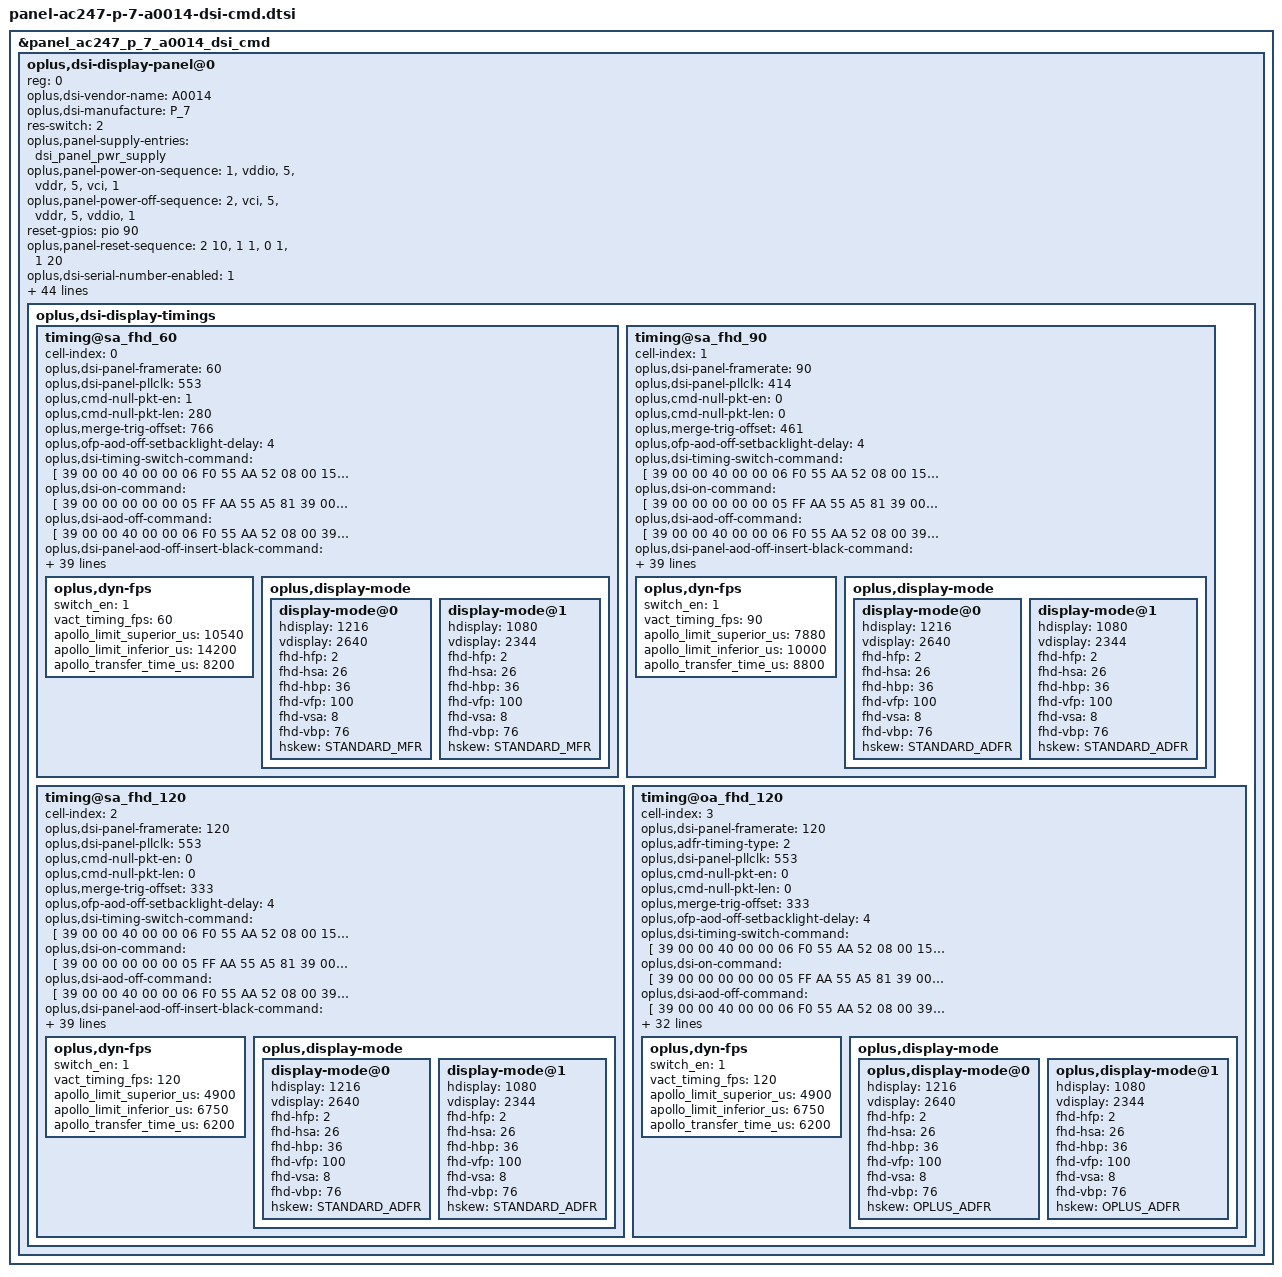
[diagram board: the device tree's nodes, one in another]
&panel_ac247_p_7_a0014_dsi_cmd {
	oplus,dsi-display-panel@0 {
		reg = <0>;
		oplus,dsi-vendor-name = "A0014";
		oplus,dsi-manufacture = "P_7";
		/* round corner */
		//#include "panel-ac247-p-7-a0014-dsi-cmd-round-corner.dtsi"
		oplus,dsi-display-timings {
			timing@sa_fhd_60 {
				cell-index = <0>;
				oplus,dsi-panel-framerate = <60>;
				oplus,dsi-panel-pllclk = <553>;
				oplus,cmd-null-pkt-en = <1>;
				oplus,cmd-null-pkt-len = <280>;
				oplus,merge-trig-offset = <766>;
				oplus,ofp-aod-off-setbacklight-delay = <4>;
				#include "panel-ac247-p-7-a0014-dsi-cmd-common.dtsi"
				oplus,dsi-timing-switch-command = [
					//2F:30->6D:01 60Hz(Repeat 1 times) --> 60Hz
					39 00 00 40 00 00 06 F0 55 AA 52 08 00
					15 00 00 40 00 00 02 6F 03
					39 00 00 40 00 00 03 35 00 01
					15 00 00 40 00 00 02 6F 20
					39 00 00 40 00 00 09 BA 00 01 03 03 00 01 03 03
					15 00 00 40 00 00 02 6F 30
					39 00 00 40 00 00 09 BA 00 01 03 0B 00 01 03 0B
					15 00 00 40 00 00 02 6F 40
					39 00 00 40 00 00 09 BA 00 01 03 17 00 01 03 17
					15 00 00 40 00 00 02 6F 50
					39 00 00 40 00 00 09 BA 00 01 03 77 00 01 03 77
					15 00 00 40 00 00 02 2F 30
					15 00 00 40 00 00 02 6D 01 //60Hz
					// DC/PWM fix
					39 00 00 40 00 00 06 F0 55 AA 52 08 09
					15 00 00 40 00 00 02 6F 1C
					39 00 00 40 00 00 06 BD 90 87 82 06 1C //Comp0_R_Gray0~4_DBV1
					15 00 00 40 00 00 02 6F 21
					39 00 00 40 00 00 06 BD 90 87 82 06 1C //Comp0_R_Gray0~4_DBV2
					15 00 00 40 00 00 02 6F 26
					39 00 00 40 00 00 06 BD 0A 07 02 86 97 //Comp0_R_Gray0~4_DBV3
					15 00 00 40 00 00 02 6F 2B
					39 00 00 40 00 00 06 BD 0A 07 02 86 97 //Comp0_R_Gray0~4_DBV4
					15 00 00 40 00 00 02 6F 3A
					39 00 00 40 00 00 06 BD 90 87 82 06 1C //Comp0_G_Gray0~4_DBV1
					15 00 00 40 00 00 02 6F 3F
					39 00 00 40 00 00 06 BD 90 87 82 06 1C //Comp0_G_Gray0~4_DBV1
					15 00 00 40 00 00 02 6F 44
					39 00 00 40 00 00 06 BD 0A 07 02 86 97 //Comp0_G_Gray0~4_DBV3
					15 00 00 40 00 00 02 6F 49
					39 00 00 40 00 00 06 BD 0A 07 02 86 97 //Comp0_G_Gray0~4_DBV4
					15 00 00 40 00 00 02 6F 58
					39 00 00 40 00 00 06 BD 90 87 82 06 1C //Comp0_B_Gray0~4_DBV1
					15 00 00 40 00 00 02 6F 5D
					39 00 00 40 00 00 06 BD 90 87 82 06 1C //Comp0_B_Gray0~4_DBV1
					15 00 00 40 00 00 02 6F 62
					39 00 00 40 00 00 06 BD 0A 07 02 86 97 //Co mp0_B_Gray0~4_DBV3
					15 00 00 40 00 00 02 6F 67
					39 00 00 00 00 00 06 BD 0A 07 02 86 97 //Comp0_B_Gray0~4_DBV4
				];
				oplus,dsi-on-command = [
					// init code
					39 00 00 00 00 00 05 FF AA 55 A5 81
					39 00 00 00 00 00 02 6F 0C
					39 00 00 00 00 00 02 FD 08
					39 00 00 00 00 00 02 6F 02
					39 00 00 00 00 00 02 F9 84
					39 00 00 00 00 00 02 6F 10
					39 00 00 00 00 00 02 FB 40
					39 00 00 00 00 00 05 FF AA 55 A5 80
					39 00 00 00 00 00 02 6F 48
					39 00 00 00 00 00 02 F2 00
					39 00 00 00 00 00 05 FF AA 55 A5 80
					39 00 00 00 00 00 02 6F 16
					39 00 00 00 00 00 03 F4 02 74
					39 00 00 00 00 00 05 FF AA 55 A5 80
					39 00 00 00 00 00 02 6F 42
					39 00 00 00 00 00 02 F4 00
					39 00 00 00 00 00 05 FF AA 55 A5 80
					39 00 00 00 00 00 02 6F 49
					39 00 00 00 00 00 02 F2 10
					39 00 00 00 00 00 05 FF AA 55 A5 81
					39 00 00 00 00 00 02 6F 05
					39 00 00 00 00 00 03 FE 3C 3C
					39 00 00 00 00 00 05 FF AA 55 A5 82
					39 00 00 00 00 00 02 6F 09
					39 00 00 00 00 00 02 F2 FF
					39 00 00 00 00 00 05 FF AA 55 A5 80
					39 00 00 00 00 00 02 6F 04
					39 00 00 00 00 00 02 F2 3C
					39 00 00 00 00 00 05 FF AA 55 A5 80
					39 00 00 00 00 00 02 6F 0A
					39 00 00 00 00 00 06 F6 70 70 70 70 70 //Power seq
					39 00 00 00 00 00 05 FF AA 55 A5 81
					39 00 00 00 00 00 02 6F 0D
					39 00 00 00 00 00 02 FB 80 // TE_opt
					39 00 00 00 00 00 06 F0 55 AA 52 08 01
					39 00 00 00 00 00 02 E5 00
					39 00 00 00 00 00 05 FF AA 55 A5 80
					39 00 00 00 00 00 02 6F 15
					39 00 00 00 00 00 03 F8 01 8C // DSPOSC=138.6MHz
					39 00 00 00 00 00 05 FF AA 55 A5 80
					39 00 00 00 00 00 02 6F 3E
					39 00 00 00 00 00 02 F8 00
					39 00 00 00 00 00 05 FF AA 55 A5 81
					39 00 00 00 00 00 02 6F 0B
					39 00 00 00 00 00 02 FD 04
					39 00 00 00 00 00 02 5A 01
					39 00 00 00 00 00 02 17 30
					39 00 00 00 00 00 03 5F 00 00
					39 00 00 00 00 00 02 35 00 // TE on
					39 00 00 00 00 00 0A 88 01 02 5F 09 4F 00 00 00 00
					39 00 00 00 00 00 02 53 20
					39 00 00 00 00 00 05 2A 00 00 04 BF
					39 00 00 00 00 00 05 2B 00 00 0A 4F
					39 00 00 00 00 00 02 90 03
					39 00 00 00 00 00 02 6F 01
					39 00 00 00 00 00 02 90 43
					39 00 00 00 00 00 13 91 AB A8 00 14 C2 00 02 31 02 05 00 08 05 0E 04 7B 10 E0 // VESA
					39 00 00 00 00 00 02 26 00
					39 00 00 00 00 00 02 6D 00
					39 00 00 00 00 00 02 6F 06
					39 00 00 00 00 00 02 6D 00
					// VFP/VBP SOP/GOP ON
					39 00 00 00 00 00 06 F0 55 AA 52 08 00
					15 00 00 00 00 00 02 6F 0D
					15 00 00 00 00 00 02 C2 0F
					//OSC：121.9-121.2 MHz
					39 00 00 00 00 00 05 FF AA 55 A5 80
					15 00 00 00 00 00 02 6F 31
					39 00 00 00 00 00 03 F8 01 B7
					// LFCC fix
					39 00 00 00 00 00 06 F0 55 AA 52 08 00
					15 00 00 00 00 00 02 6F 08
					15 00 00 00 00 00 02 B2 C0
					39 00 00 00 00 00 06 F0 55 AA 52 08 09
					//Comp_DBVPNTS0~5 = 423h,424h,48Ah,48Bh,4F0h,4F1h
					15 00 00 00 00 00 02 6F 01
					39 00 00 00 00 00 0A BD 44 23 24 44 8A 8B 44 F0 F1
					// Fixed TE
					15 00 00 00 00 00 02 5A 00
					15 00 00 00 00 00 02 6F 03
					15 00 00 00 00 00 02 5A 00
					39 00 00 00 00 00 03 44 00 00
					15 00 00 00 00 00 02 6F 04
					39 00 00 00 00 00 0D 44 00 00 00 00 00 00 00 00 00 00 00 00
					39 00 00 00 00 00 06 F0 55 AA 52 08 00
					15 00 00 00 00 00 02 BE 47
					// TEST TE
					39 00 00 00 00 00 06 F0 55 AA 52 08 00
					15 00 00 00 00 00 02 6F 01
					15 00 00 00 00 00 02 BE 54
					39 00 00 00 00 00 06 F0 55 AA 52 08 00
					15 00 00 00 00 00 02 6F 07
					39 00 00 00 00 00 06 B5 4E 2C 00 00 00 //Nor ELVSS 2.3V,ELVDD 4.8V
					15 00 00 00 00 00 02 6F 0C
					39 00 00 00 00 00 06 B5 4E 35 00 00 00 //AOD ELVSS 1.4V,ELVDD 4.8V
					//2F:30->6D:01 60Hz(Repeat 1 times) --> 60Hz
					39 00 00 00 00 00 06 F0 55 AA 52 08 00
					15 00 00 00 00 00 02 6F 03
					39 00 00 00 00 00 03 35 00 01
					15 00 00 00 00 00 02 6F 20
					39 00 00 00 00 00 09 BA 00 01 03 03 00 01 03 03
					15 00 00 00 00 00 02 6F 30
					39 00 00 00 00 00 09 BA 00 01 03 0B 00 01 03 0B
					15 00 00 00 00 00 02 6F 40
					39 00 00 00 00 00 09 BA 00 01 03 17 00 01 03 17
					15 00 00 00 00 00 02 6F 50
					39 00 00 00 00 00 09 BA 00 01 03 77 00 01 03 77
					15 00 00 00 00 00 02 2F 30
					15 00 00 00 00 00 02 6D 01 //60Hz
					// DC/PWM fix
					39 00 00 00 00 00 06 F0 55 AA 52 08 09
					15 00 00 00 00 00 02 6F 1C
					39 00 00 00 00 00 06 BD 90 87 82 06 1C //Comp0_R_Gray0~4_DBV1
					15 00 00 00 00 00 02 6F 21
					39 00 00 00 00 00 06 BD 90 87 82 06 1C //Comp0_R_Gray0~4_DBV2
					15 00 00 00 00 00 02 6F 26
					39 00 00 00 00 00 06 BD 0A 07 02 86 97 //Comp0_R_Gray0~4_DBV3
					15 00 00 00 00 00 02 6F 2B
					39 00 00 00 00 00 06 BD 0A 07 02 86 97 //Comp0_R_Gray0~4_DBV4
					15 00 00 00 00 00 02 6F 3A
					39 00 00 00 00 00 06 BD 90 87 82 06 1C //Comp0_G_Gray0~4_DBV1
					15 00 00 00 00 00 02 6F 3F
					39 00 00 00 00 00 06 BD 90 87 82 06 1C //Comp0_G_Gray0~4_DBV1
					15 00 00 00 00 00 02 6F 44
					39 00 00 00 00 00 06 BD 0A 07 02 86 97 //Comp0_G_Gray0~4_DBV3
					15 00 00 00 00 00 02 6F 49
					39 00 00 00 00 00 06 BD 0A 07 02 86 97 //Comp0_G_Gray0~4_DBV4
					15 00 00 00 00 00 02 6F 58
					39 00 00 00 00 00 06 BD 90 87 82 06 1C //Comp0_B_Gray0~4_DBV1
					15 00 00 00 00 00 02 6F 5D
					39 00 00 00 00 00 06 BD 90 87 82 06 1C //Comp0_B_Gray0~4_DBV1
					15 00 00 00 00 00 02 6F 62
					39 00 00 00 00 00 06 BD 0A 07 02 86 97 //Co mp0_B_Gray0~4_DBV3
					15 00 00 00 00 00 02 6F 67
					39 00 00 00 00 00 06 BD 0A 07 02 86 97 //Comp0_B_Gray0~4_DBV4
					// fix odc green ghosting
					39 00 00 00 00 00 06 F0 55 AA 52 08 08
					39 00 00 00 00 00 05 E0 21 01 01 01
					39 00 00 00 00 00 02 6F 35
					39 00 00 00 00 00 02 E2 00
					39 00 00 00 00 00 02 6F 43
					39 00 00 00 00 00 02 E2 00
					39 00 00 00 00 00 02 6F 51
					39 00 00 00 00 00 02 E2 00
					39 00 00 00 00 00 02 6F 5F
					39 00 00 00 00 00 02 E2 00
					39 00 00 00 00 00 02 6F 6D
					39 00 00 00 00 00 02 E2 00
					39 00 00 00 00 00 02 6F 7B
					39 00 00 00 00 00 02 E2 00
					// Demura LLC impro
					39 00 00 00 00 00 06 F0 55 AA 52 08 04
					39 00 00 00 00 00 08 E1 87 07 07 03 03 03 03
					15 00 00 00 00 00 02 6F 07
					39 00 00 00 00 00 05 03 01 01 01 01
					15 00 00 00 00 00 02 6F 0C
					39 00 00 00 00 00 08 E1 00 00 00 00 00 00 00
					15 00 00 00 00 00 02 6F 13
					39 00 00 00 00 00 05 00 00 00 00 00
					15 00 00 00 00 00 02 6F 18
					39 00 00 00 00 00 08 E1 07 07 07 03 03 03 03
					15 00 00 00 00 00 02 6F 1F
					39 00 00 00 00 00 05 03 01 01 01 01
					15 00 00 00 00 00 02 6F 24
					39 00 00 00 00 00 08 E1 01 03 15 1E 2E 3E 48
					15 00 00 00 00 00 02 6F 2B
					39 00 00 00 00 00 05 49 75 B1 DB FF
					// 3d lut inpro L240
					39 00 00 00 00 00 06 F0 55 AA 52 08 00
					39 00 00 00 00 00 02 6F 02
					39 00 00 00 00 00 07 E6 00 01 00 BC 01 5E
					39 00 00 00 00 00 02 6F 17
					39 00 00 00 00 00 02 E6 01
					39 00 00 00 00 00 06 F0 55 AA 52 08 00
					39 00 00 00 00 00 02 E6 80
					39 00 00 00 00 00 02 6F 00
					39 00 00 00 00 00 19 E7 00 00 00 00 00 00 00 00 00 00 00 00 00 00 00 00 00 00 00 00 00 00 00 00
					39 00 00 00 00 00 02 6F 18
					39 00 00 00 00 00 19 E7 00 40 40 40 40 40 40 40 40 40 40 40 40 40 40 40 40 40 40 40 40 40 40 40
					39 00 00 00 00 00 02 6F 30
					39 00 00 00 00 00 19 E7 40 40 80 80 80 80 80 80 80 80 80 80 80 80 80 80 80 80 80 80 80 80 80 80
					39 00 00 00 00 00 02 6F 48
					39 00 00 00 00 00 19 E7 80 80 80 C0 C0 C0 C0 C0 C0 C0 C0 C0 C0 C0 C0 C0 C0 C0 C0 C0 C0 C0 C0 C0
					39 00 00 00 00 00 02 6F 60
					39 00 00 00 00 00 19 E7 C0 C0 C0 C0 FF FF FF FF FF FF FF FF FF FF FF FF FF FF FF FF FF FF FF FF
					39 00 00 00 00 00 02 6F 78
					39 00 00 00 00 00 19 E7 FF FF FF FF FF 00 00 00 00 00 40 40 40 40 40 80 80 80 80 80 C0 C0 C0 C0
					39 00 00 00 00 00 02 6F 90
					39 00 00 00 00 00 19 E7 C0 FF FF FF FF FF 00 00 00 00 00 40 40 40 40 40 80 80 80 80 80 C0 C0 C0
					39 00 00 00 00 00 02 6F A8
					39 00 00 00 00 00 19 E7 C0 C0 FF FF FF FF FF 00 00 00 00 00 40 40 40 40 40 80 80 80 80 80 C0 C0
					39 00 00 00 00 00 02 6F C0
					39 00 00 00 00 00 19 E7 C0 C0 C0 FF FF FF FF FF 00 00 00 00 00 40 40 40 40 40 80 80 80 80 80 C0
					39 00 00 00 00 00 02 6F D8
					39 00 00 00 00 00 19 E7 C0 C0 C0 C0 FF FF FF FF FF 00 00 00 00 00 40 40 40 40 40 80 80 80 80 80
					39 00 00 00 00 00 02 6F 00
					39 00 00 00 00 00 19 E8 C0 C0 C0 C0 C0 FF FF FF FF FF 00 40 80 C0 FF 00 40 80 C0 FF 00 40 80 C0
					39 00 00 00 00 00 02 6F 18
					39 00 00 00 00 00 19 E8 FF 00 40 80 C0 FF 00 40 80 C0 FF 00 40 80 C0 FF 00 40 80 C0 FF 00 40 80
					39 00 00 00 00 00 02 6F 30
					39 00 00 00 00 00 19 E8 C0 FF 00 40 80 C0 FF 00 40 80 C0 FF 00 40 80 C0 FF 00 40 80 C0 FF 00 40
					39 00 00 00 00 00 02 6F 48
					39 00 00 00 00 00 19 E8 80 C0 FF 00 40 80 C0 FF 00 40 80 C0 FF 00 40 80 C0 FF 00 40 80 C0 FF 00
					39 00 00 00 00 00 02 6F 60
					39 00 00 00 00 00 19 E8 40 80 C0 FF 00 40 80 C0 FF 00 40 80 C0 FF 00 40 80 C0 FF 00 40 80 C0 FF
					39 00 00 00 00 00 02 6F 78
					39 00 00 00 00 00 19 E8 00 40 80 C0 FF 00 40 80 C0 FF 00 40 80 C0 FF 08 10 18 20 28 30 38 48 50
					39 00 00 00 00 00 02 6F 90
					39 00 00 00 00 00 19 E8 58 60 68 70 78 88 90 98 A0 A8 B0 B8 C8 D0 D8 E0 E8 F0 F8 08 10 18 20 28
					39 00 00 00 00 00 02 6F A8
					39 00 00 00 00 00 19 E8 30 38 48 50 58 60 68 70 78 88 90 98 A0 A8 B0 B8 C8 D0 D8 E0 E8 F0 F8 08
					39 00 00 00 00 00 02 6F C0
					39 00 00 00 00 00 19 E8 10 18 20 28 30 38 48 50 58 60 68 70 78 88 90 98 A0 A8 B0 B8 C8 D0 D8 E0
					39 00 00 00 00 00 02 6F D8
					39 00 00 00 00 00 19 E8 E8 F0 F8 10 10 00 20 10 10 10 00 10 10 20 10 00 10 10 10 10 20 00 00 00
					39 00 00 00 00 00 02 E6 00
					39 00 00 00 00 00 06 F0 55 AA 52 08 00
					39 00 00 00 00 00 02 E6 81
					39 00 00 00 00 00 02 6F 00
					39 00 00 00 00 00 19 E7 00 00 00 00 00 00 00 00 00 00 00 00 00 00 00 00 00 00 00 00 00 00 00 00
					39 00 00 00 00 00 02 6F 18
					39 00 00 00 00 00 19 E7 00 40 40 40 40 40 40 40 40 40 40 40 40 40 40 40 40 40 40 40 40 40 40 40
					39 00 00 00 00 00 02 6F 30
					39 00 00 00 00 00 19 E7 40 40 80 80 80 80 80 80 80 80 80 80 80 80 80 80 80 80 80 80 80 80 80 80
					39 00 00 00 00 00 02 6F 48
					39 00 00 00 00 00 19 E7 80 80 80 C0 C0 C0 C0 C0 C0 C0 C0 C0 C0 C0 C0 C0 C0 C0 C0 C0 C0 C0 C0 C0
					39 00 00 00 00 00 02 6F 60
					39 00 00 00 00 00 19 E7 C0 C0 C0 C0 FF FF FF FF FF FF FF FF FF FF FF FF FF FF FF FF FF FF FF FF
					39 00 00 00 00 00 02 6F 78
					39 00 00 00 00 00 19 E7 FF FF FF FF FF 00 00 00 00 00 40 40 40 40 40 80 80 80 80 80 C0 C0 C0 C0
					39 00 00 00 00 00 02 6F 90
					39 00 00 00 00 00 19 E7 C0 FF FF FF FF FF 00 00 00 00 00 40 40 40 40 40 80 80 80 80 80 C0 C0 C0
					39 00 00 00 00 00 02 6F A8
					39 00 00 00 00 00 19 E7 C0 C0 FF FF FF FF FF 00 00 00 00 00 40 40 40 40 40 80 80 80 80 80 C0 C0
					39 00 00 00 00 00 02 6F C0
					39 00 00 00 00 00 19 E7 C0 C0 C0 FF FF FF FF FF 00 00 00 00 00 40 40 40 40 40 80 80 80 80 80 C0
					39 00 00 00 00 00 02 6F D8
					39 00 00 00 00 00 19 E7 C0 C0 C0 C0 FF FF FF FF FF 00 00 00 00 00 40 40 40 40 40 80 80 80 80 80
					39 00 00 00 00 00 02 6F 00
					39 00 00 00 00 00 19 E8 C0 C0 C0 C0 C0 FF FF FF FF FF 00 40 80 C0 FF 00 40 80 C0 FF 00 40 80 C0
					39 00 00 00 00 00 02 6F 18
					39 00 00 00 00 00 19 E8 FF 00 40 80 C0 FF 00 40 80 C0 FF 00 40 80 C0 FF 00 40 80 C0 FF 00 40 80
					39 00 00 00 00 00 02 6F 30
					39 00 00 00 00 00 19 E8 C0 FF 00 40 80 C0 FF 00 40 80 C0 FF 00 40 80 C0 FF 00 40 80 C0 FF 00 40
					39 00 00 00 00 00 02 6F 48
					39 00 00 00 00 00 19 E8 80 C0 FF 00 40 80 C0 FF 00 40 80 C0 FF 00 40 80 C0 FF 00 40 80 C0 FF 00
					39 00 00 00 00 00 02 6F 60
					39 00 00 00 00 00 19 E8 40 80 C0 FF 00 40 80 C0 FF 00 40 80 C0 FF 00 40 80 C0 FF 00 40 80 C0 FF
					39 00 00 00 00 00 02 6F 78
					39 00 00 00 00 00 19 E8 00 40 80 C0 FF 00 40 80 C0 FF 00 40 80 C0 FF 08 10 18 20 28 30 38 48 50
					39 00 00 00 00 00 02 6F 90
					39 00 00 00 00 00 19 E8 58 60 68 70 78 86 8E 95 9D A5 AE B7 C8 D0 D8 E0 E8 F0 F8 08 10 18 20 28
					39 00 00 00 00 00 02 6F A8
					39 00 00 00 00 00 19 E8 30 38 48 50 58 60 68 70 78 88 90 98 A0 A8 B0 B8 C6 CD D4 DC E5 EE F8 08
					39 00 00 00 00 00 02 6F C0
					39 00 00 00 00 00 19 E8 10 18 20 28 30 38 48 50 58 60 68 70 78 88 90 98 A0 A8 B0 B8 C8 D0 D8 E0
					39 00 00 00 00 00 02 6F D8
					39 00 00 00 00 00 19 E8 E8 F0 F8 10 10 00 20 10 10 10 00 10 10 20 10 00 10 10 10 10 20 00 00 00
					39 00 00 00 00 00 02 E6 00
					39 00 00 00 00 00 06 F0 55 AA 52 08 00
					39 00 00 00 00 00 02 E6 82
					39 00 00 00 00 00 02 6F 00
					39 00 00 00 00 00 19 E7 00 00 00 00 00 00 00 00 00 00 00 00 00 00 00 00 00 00 00 00 00 00 00 00
					39 00 00 00 00 00 02 6F 18
					39 00 00 00 00 00 19 E7 00 40 40 40 40 40 40 40 40 40 40 40 40 40 40 40 40 40 40 40 40 40 40 40
					39 00 00 00 00 00 02 6F 30
					39 00 00 00 00 00 19 E7 40 40 80 80 80 80 80 80 80 80 80 80 80 80 80 80 80 80 80 80 80 80 80 80
					39 00 00 00 00 00 02 6F 48
					39 00 00 00 00 00 19 E7 80 80 80 C0 C0 C0 C0 C0 C0 C0 C0 C0 C0 C0 C0 C0 C0 C0 C0 C0 C0 C0 C0 C0
					39 00 00 00 00 00 02 6F 60
					39 00 00 00 00 00 19 E7 C0 C0 C0 C0 FF FF FF FF FF FF FF FF FF FF FF FF FF FF FF FF FF FF FF FF
					39 00 00 00 00 00 02 6F 78
					39 00 00 00 00 00 19 E7 FF FF FF FF FF 00 00 00 00 00 40 40 40 40 40 80 80 80 80 80 C0 C0 C0 C0
					39 00 00 00 00 00 02 6F 90
					39 00 00 00 00 00 19 E7 C0 FF FF FF FF FF 00 00 00 00 00 40 40 40 40 40 80 80 80 80 80 C0 C0 C0
					39 00 00 00 00 00 02 6F A8
					39 00 00 00 00 00 19 E7 C0 C0 FF FF FF FF FF 00 00 00 00 00 40 40 40 40 40 80 80 80 80 80 C0 C0
					39 00 00 00 00 00 02 6F C0
					39 00 00 00 00 00 19 E7 C0 C0 C0 FF FF FF FF FF 00 00 00 00 00 40 40 40 40 40 80 80 80 80 80 C0
					39 00 00 00 00 00 02 6F D8
					39 00 00 00 00 00 19 E7 C0 C0 C0 C0 FF FF FF FF FF 00 00 00 00 00 40 40 40 40 40 80 80 80 80 80
					39 00 00 00 00 00 02 6F 00
					39 00 00 00 00 00 19 E8 C0 C0 C0 C0 C0 FF FF FF FF FF 00 40 80 C0 FF 00 40 80 C0 FF 00 40 80 C0
					39 00 00 00 00 00 02 6F 18
					39 00 00 00 00 00 19 E8 FF 00 40 80 C0 FF 00 40 80 C0 FF 00 40 80 C0 FF 00 40 80 C0 FF 00 40 80
					39 00 00 00 00 00 02 6F 30
					39 00 00 00 00 00 19 E8 C0 FF 00 40 80 C0 FF 00 40 80 C0 FF 00 40 80 C0 FF 00 40 80 C0 FF 00 40
					39 00 00 00 00 00 02 6F 48
					39 00 00 00 00 00 19 E8 80 C0 FF 00 40 80 C0 FF 00 40 80 C0 FF 00 40 80 C0 FF 00 40 80 C0 FF 00
					39 00 00 00 00 00 02 6F 60
					39 00 00 00 00 00 19 E8 40 80 C0 FF 00 40 80 C0 FF 00 40 80 C0 FF 00 40 80 C0 FF 00 40 80 C0 FF
					39 00 00 00 00 00 02 6F 78
					39 00 00 00 00 00 19 E8 00 40 80 C0 FF 00 40 80 C0 FF 00 40 80 C0 FF 08 10 18 20 28 30 38 48 50
					39 00 00 00 00 00 02 6F 90
					39 00 00 00 00 00 19 E8 58 60 68 70 78 88 90 98 A0 A8 B0 B8 C8 D0 D8 E0 E8 F0 F8 08 10 18 20 28
					39 00 00 00 00 00 02 6F A8
					39 00 00 00 00 00 19 E8 30 38 48 50 58 60 68 70 78 88 90 98 A0 A8 B0 B8 C8 D0 D8 E0 E8 F0 F8 08
					39 00 00 00 00 00 02 6F C0
					39 00 00 00 00 00 19 E8 10 18 20 28 30 38 48 50 58 60 68 70 78 88 90 98 A0 A8 B0 B8 C8 D0 D8 E0
					39 00 00 00 00 00 02 6F D8
					39 00 00 00 00 00 19 E8 E8 F0 F8 10 10 00 20 10 10 10 00 10 10 20 10 00 10 10 10 10 20 00 00 00
					39 00 00 00 00 00 02 E6 00
					39 00 00 00 00 00 02 57 80
					//osc fixed
					39 00 00 00 00 00 06 F0 55 AA 52 08 01
					39 00 00 00 00 00 06 C3 DD 06 20 11 FF
					15 00 00 00 00 00 02 6F 05
					39 00 00 00 00 00 06 C3 00 06 20 11 FF
					15 00 00 00 00 00 02 6F 0A
					39 00 00 00 00 00 06 C3 00 07 0E 20 06
					15 00 00 00 00 00 02 6F 0F
					39 00 00 00 00 00 06 C3 44 19 07 11 18
					15 00 00 00 00 00 02 6F 14
					39 00 00 00 00 00 06 C3 06 5C 13 07 0E
					15 00 00 00 00 00 02 6F 19
					39 00 00 00 00 00 06 C3 20 06 44 19 07
					15 00 00 00 00 00 02 6F 1E
					39 00 00 00 00 00 06 C3 0E 20 06 44 19
					15 00 00 00 00 00 02 6F 23
					39 00 00 00 00 00 06 C3 07 0E 20 06 44
					15 00 00 00 00 00 02 6F 28
					15 00 00 00 00 00 02 C3 19
					//Modify power-off timing
					39 00 00 00 00 00 06 F0 55 AA 52 08 03
					15 00 00 00 00 00 02 6F 07
					15 00 00 00 00 00 02 C6 48
					//Light On
					39 00 00 00 78 00 01 11 // Sleep out
					39 00 00 00 00 00 01 29 // Display out
				];
				oplus,dsi-aod-off-command = [
					39 00 00 40 00 00 06 F0 55 AA 52 08 00
					39 00 00 40 00 00 02 2F 30
					39 00 00 40 00 00 02 6F 03
					39 00 00 40 00 00 03 35 00 01
					39 00 00 40 00 00 02 38 00
					05 00 00 40 00 00 01 2C
					39 00 00 40 00 00 03 51 00 00
					39 00 00 40 00 00 06 F0 55 AA 52 08 08
					39 00 00 40 00 00 02 BE 03
					39 00 00 40 00 00 05 FF AA 55 A5 81
					39 00 00 40 00 00 02 6F 0B
					39 00 00 00 00 00 02 FD 04 //gmaconv on
				];
				oplus,dsi-panel-aod-off-insert-black-command = [
					39 00 00 40 00 00 06 F0 55 AA 52 08 00
					39 00 00 40 00 00 02 2F 30
					39 00 00 40 00 00 02 6F 03
					39 00 00 40 00 00 03 35 00 01
					39 00 00 40 00 00 02 38 00
					39 00 00 40 00 00 03 51 00 00
					39 00 00 40 00 00 06 F0 55 AA 52 08 08
					39 00 00 40 00 00 02 BE 03
					39 00 00 40 00 00 05 FF AA 55 A5 81
					39 00 00 40 00 00 02 6F 0B
					39 00 00 00 00 00 02 FD 04 //gmaconv on
				];
				oplus,dsi-ultra-low-power-aod-on-command = [
					39 00 00 40 00 00 06 F0 55 AA 52 08 00
					39 00 00 40 00 00 02 6F 18
					39 00 00 00 00 00 06 BB 01 00 02 02 00
				];
				oplus,dsi-ultra-low-power-aod-off-command = [
					39 00 00 40 00 00 06 F0 55 AA 52 08 00
					39 00 00 40 00 00 02 6F 18
					39 00 00 00 00 00 06 BB 01 00 00 00 00
				];
				oplus,dsi-hbm-on-command = [
					39 00 00 00 00 00 03 51 0F FE
				];
				oplus,dsi-hbm-off-command = [
					39 00 00 00 00 00 03 51 0D BB
				];
				oplus,dsi-adfr-min-fps-60hz-command = [
					39 00 00 40 00 00 06 F0 55 AA 52 08 09
					15 00 00 40 00 00 02 6F 1C
					39 00 00 40 00 00 06 BD 90 87 82 06 1C
					15 00 00 40 00 00 02 6F 21
					39 00 00 40 00 00 06 BD 90 87 82 06 1C
					15 00 00 40 00 00 02 6F 26
					39 00 00 40 00 00 06 BD 0A 07 02 86 97
					15 00 00 40 00 00 02 6F 2B
					39 00 00 40 00 00 06 BD 0A 07 02 86 97
					15 00 00 40 00 00 02 6F 3A
					39 00 00 40 00 00 06 BD 90 87 82 06 1C
					15 00 00 40 00 00 02 6F 3F
					39 00 00 40 00 00 06 BD 90 87 82 06 1C
					15 00 00 40 00 00 02 6F 44
					39 00 00 40 00 00 06 BD 0A 07 02 86 97
					15 00 00 40 00 00 02 6F 49
					39 00 00 40 00 00 06 BD 0A 07 02 86 97
					15 00 00 40 00 00 02 6F 58
					39 00 00 40 00 00 06 BD 90 87 82 06 1C
					15 00 00 40 00 00 02 6F 5D
					39 00 00 40 00 00 06 BD 90 87 82 06 1C
					15 00 00 40 00 00 02 6F 62
					39 00 00 40 00 00 06 BD 0A 07 02 86 97
					15 00 00 40 00 00 02 6F 67
					39 00 00 40 00 00 06 BD 0A 07 02 86 97
					39 00 00 40 00 00 02 2F 30
					39 00 00 00 00 00 02 6D 01
				];
				oplus,dsi-adfr-min-fps-30hz-command = [
					39 00 00 40 00 00 06 F0 55 AA 52 08 09
					15 00 00 40 00 00 02 6F 1C
					39 00 00 40 00 00 06 BD 90 87 82 06 1C
					15 00 00 40 00 00 02 6F 21
					39 00 00 40 00 00 06 BD 90 87 82 06 1C
					15 00 00 40 00 00 02 6F 26
					39 00 00 40 00 00 06 BD 0A 07 02 86 97
					15 00 00 40 00 00 02 6F 2B
					39 00 00 40 00 00 06 BD 0A 07 02 86 97
					15 00 00 40 00 00 02 6F 3A
					39 00 00 40 00 00 06 BD 90 87 82 06 1C
					15 00 00 40 00 00 02 6F 3F
					39 00 00 40 00 00 06 BD 90 87 82 06 1C
					15 00 00 40 00 00 02 6F 44
					39 00 00 40 00 00 06 BD 0A 07 02 86 97
					15 00 00 40 00 00 02 6F 49
					39 00 00 40 00 00 06 BD 0A 07 02 86 97
					15 00 00 40 00 00 02 6F 58
					39 00 00 40 00 00 06 BD 90 87 82 06 1C
					15 00 00 40 00 00 02 6F 5D
					39 00 00 40 00 00 06 BD 90 87 82 06 1C
					15 00 00 40 00 00 02 6F 62
					39 00 00 40 00 00 06 BD 0A 07 02 86 97
					15 00 00 40 00 00 02 6F 67
					39 00 00 40 00 00 06 BD 0A 07 02 86 97
					39 00 00 40 00 00 02 2F 30
					39 00 00 00 00 00 02 6D 03
				];
				oplus,dsi-adfr-min-fps-10hz-command = [
					39 00 00 40 00 00 06 F0 55 AA 52 08 09
					15 00 00 40 00 00 02 6F 1C
					39 00 00 40 00 00 06 BD 90 87 82 06 1C
					15 00 00 40 00 00 02 6F 21
					39 00 00 40 00 00 06 BD 90 87 82 06 1C
					15 00 00 40 00 00 02 6F 26
					39 00 00 40 00 00 06 BD 0A 07 02 86 97
					15 00 00 40 00 00 02 6F 2B
					39 00 00 40 00 00 06 BD 0A 07 02 86 97
					15 00 00 40 00 00 02 6F 3A
					39 00 00 40 00 00 06 BD 90 87 82 06 1C
					15 00 00 40 00 00 02 6F 3F
					39 00 00 40 00 00 06 BD 90 87 82 06 1C
					15 00 00 40 00 00 02 6F 44
					39 00 00 40 00 00 06 BD 0A 07 02 86 97
					15 00 00 40 00 00 02 6F 49
					39 00 00 40 00 00 06 BD 0A 07 02 86 97
					15 00 00 40 00 00 02 6F 58
					39 00 00 40 00 00 06 BD 90 87 82 06 1C
					15 00 00 40 00 00 02 6F 5D
					39 00 00 40 00 00 06 BD 90 87 82 06 1C
					15 00 00 40 00 00 02 6F 62
					39 00 00 40 00 00 06 BD 0A 07 02 86 97
					15 00 00 40 00 00 02 6F 67
					39 00 00 40 00 00 06 BD 0A 07 02 86 97
					39 00 00 40 00 00 02 2F 30
					39 00 00 00 00 00 02 6D 05
				];
				oplus,dsi-adfr-min-fps-1hz-command = [
					39 00 00 40 00 00 06 F0 55 AA 52 08 09
					15 00 00 40 00 00 02 6F 1C
					39 00 00 40 00 00 06 BD 90 87 82 06 1C
					15 00 00 40 00 00 02 6F 21
					39 00 00 40 00 00 06 BD 90 87 82 06 1C
					15 00 00 40 00 00 02 6F 26
					39 00 00 40 00 00 06 BD 0A 07 02 86 97
					15 00 00 40 00 00 02 6F 2B
					39 00 00 40 00 00 06 BD 0A 07 02 86 97
					15 00 00 40 00 00 02 6F 3A
					39 00 00 40 00 00 06 BD 90 87 82 06 1C
					15 00 00 40 00 00 02 6F 3F
					39 00 00 40 00 00 06 BD 90 87 82 06 1C
					15 00 00 40 00 00 02 6F 44
					39 00 00 40 00 00 06 BD 0A 07 02 86 97
					15 00 00 40 00 00 02 6F 49
					39 00 00 40 00 00 06 BD 0A 07 02 86 97
					15 00 00 40 00 00 02 6F 58
					39 00 00 40 00 00 06 BD 90 87 82 06 1C
					15 00 00 40 00 00 02 6F 5D
					39 00 00 40 00 00 06 BD 90 87 82 06 1C
					15 00 00 40 00 00 02 6F 62
					39 00 00 40 00 00 06 BD 0A 07 02 86 97
					15 00 00 40 00 00 02 6F 67
					39 00 00 40 00 00 06 BD 0A 07 02 86 97
					39 00 00 40 00 00 02 2F 30
					39 00 00 00 00 00 02 6D 07
				];
				oplus,dsi-timing-switch-command-state = "dsi_hs_mode";
				oplus,dsi-on-command-state = "dsi_lp_mode";
				oplus,dsi-aod-off-command-state = "dsi_ls_mode";
				oplus,dsi-panel-aod-off-insert-black-command-state = "dsi_ls_mode";
				oplus,dsi-ultra-low-power-aod-on-command-state = "dsi_ls_mode";
				oplus,dsi-ultra-low-power-aod-off-command-state = "dsi_ls_mode";
				oplus,dsi-hbm-on-command-state = "dsi_hs_mode";
				oplus,dsi-hbm-off-command-state = "dsi_hs_mode";
				oplus,dsi-adfr-min-fps-60hz-command-state = "dsi_hs_mode";
				oplus,dsi-adfr-min-fps-30hz-command-state = "dsi_hs_mode";
				oplus,dsi-adfr-min-fps-10hz-command-state = "dsi_hs_mode";
				oplus,dsi-adfr-min-fps-1hz-command-state = "dsi_hs_mode";
				oplus,dsc-params-entries = <&dsc_params>;
				oplus,spr-params-entries = <&spr_params>;
				oplus,dyn-fps {
					switch_en = <1>;
					vact_timing_fps = <60>;
					apollo_limit_superior_us = <10540>;
					apollo_limit_inferior_us = <14200>;
					apollo_transfer_time_us = <8200>;
				};
				oplus,display-mode {
					display-mode@0 {
						hdisplay = <1216>;
						vdisplay = <2640>;
						fhd-hfp = <2>;
						fhd-hsa = <26>;
						fhd-hbp = <36>;
						fhd-vfp = <100>;
						fhd-vsa = <8>;
						fhd-vbp = <76>;
						hskew = <STANDARD_MFR>;
					};
					display-mode@1 {
						hdisplay = <1080>;
						vdisplay = <2344>;
						fhd-hfp = <2>;
						fhd-hsa = <26>;
						fhd-hbp = <36>;
						fhd-vfp = <100>;
						fhd-vsa = <8>;
						fhd-vbp = <76>;
						hskew = <STANDARD_MFR>;
					};
				};
			};
			timing@sa_fhd_90 {
				cell-index = <1>;
				oplus,dsi-panel-framerate = <90>;
				oplus,dsi-panel-pllclk = <414>;
				oplus,cmd-null-pkt-en = <0>;
				oplus,cmd-null-pkt-len = <0>;
				oplus,merge-trig-offset = <461>;
				oplus,ofp-aod-off-setbacklight-delay = <4>;
				#include "panel-ac247-p-7-a0014-dsi-cmd-common.dtsi"
				oplus,dsi-timing-switch-command = [
					//90HZ
					39 00 00 40 00 00 06 F0 55 AA 52 08 00
					15 00 00 40 00 00 02 6F 03
					39 00 00 40 00 00 03 35 00 00
					15 00 00 40 00 00 02 6F 20
					39 00 00 40 00 00 09 BA 00 01 02 02 00 01 02 02
					15 00 00 40 00 00 02 6F 30
					39 00 00 40 00 00 09 BA 00 01 02 08 00 01 02 08
					15 00 00 40 00 00 02 6F 40
					39 00 00 40 00 00 09 BA 00 01 02 11 00 01 02 11
					15 00 00 40 00 00 02 6F 50
					39 00 00 40 00 00 09 BA 00 01 02 59 00 01 02 59
					15 00 00 40 00 00 02 2F 31
					15 00 00 40 00 00 02 6D 08 //90Hz
					// DC/PWM fix
					39 00 00 40 00 00 06 F0 55 AA 52 08 09
					15 00 00 40 00 00 02 6F 1C
					39 00 00 40 00 00 06 BD 98 89 84 02 15 //Comp0_R_Gray0~4_DBV1
					15 00 00 40 00 00 02 6F 21
					39 00 00 40 00 00 06 BD 98 89 84 02 15 //Comp0_R_Gray0~4_DBV2
					15 00 00 40 00 00 02 6F 26
					39 00 00 40 00 00 06 BD 12 09 04 86 97 //Comp0_R_Gray0~4_DBV3
					15 00 00 40 00 00 02 6F 2B
					39 00 00 40 00 00 06 BD 12 09 04 86 97 //Comp0_R_Gray0~4_DBV4
					15 00 00 40 00 00 02 6F 3A
					39 00 00 40 00 00 06 BD 98 89 84 02 15 //Comp0_G_Gray0~4_DBV1
					15 00 00 40 00 00 02 6F 3F
					39 00 00 40 00 00 06 BD 98 89 84 02 15 //Comp0_G_Gray0~4_DBV1
					15 00 00 40 00 00 02 6F 44
					39 00 00 40 00 00 06 BD 12 09 04 86 97 //Comp0_G_Gray0~4_DBV3
					15 00 00 40 00 00 02 6F 49
					39 00 00 40 00 00 06 BD 12 09 04 86 97 //Comp0_G_Gray0~4_DBV4
					15 00 00 40 00 00 02 6F 58
					39 00 00 40 00 00 06 BD 98 89 84 02 15 //Comp 0_B_Gray0~4_DBV1
					15 00 00 40 00 00 02 6F 5D
					39 00 00 40 00 00 06 BD 98 89 84 02 15 //Comp0_B_Gray0~4_DBV1
					15 00 00 40 00 00 02 6F 62
					39 00 00 40 00 00 06 BD 12 09 04 86 97 //Comp0_B_Gray0~4_DBV3
					15 00 00 40 00 00 02 6F 67
					39 00 00 00 00 00 06 BD 12 09 04 86 97 //Comp0_B_Gray0~4_DBV4
				];
				oplus,dsi-on-command = [
					// init code
					39 00 00 00 00 00 05 FF AA 55 A5 81
					39 00 00 00 00 00 02 6F 0C
					39 00 00 00 00 00 02 FD 08
					39 00 00 00 00 00 02 6F 02
					39 00 00 00 00 00 02 F9 84
					39 00 00 00 00 00 02 6F 10
					39 00 00 00 00 00 02 FB 40
					39 00 00 00 00 00 05 FF AA 55 A5 80
					39 00 00 00 00 00 02 6F 48
					39 00 00 00 00 00 02 F2 00
					39 00 00 00 00 00 05 FF AA 55 A5 80
					39 00 00 00 00 00 02 6F 16
					39 00 00 00 00 00 03 F4 02 74
					39 00 00 00 00 00 05 FF AA 55 A5 80
					39 00 00 00 00 00 02 6F 42
					39 00 00 00 00 00 02 F4 00
					39 00 00 00 00 00 05 FF AA 55 A5 80
					39 00 00 00 00 00 02 6F 49
					39 00 00 00 00 00 02 F2 10
					39 00 00 00 00 00 05 FF AA 55 A5 81
					39 00 00 00 00 00 02 6F 05
					39 00 00 00 00 00 03 FE 3C 3C
					39 00 00 00 00 00 05 FF AA 55 A5 82
					39 00 00 00 00 00 02 6F 09
					39 00 00 00 00 00 02 F2 FF
					39 00 00 00 00 00 05 FF AA 55 A5 80
					39 00 00 00 00 00 02 6F 04
					39 00 00 00 00 00 02 F2 3C
					39 00 00 00 00 00 05 FF AA 55 A5 80
					39 00 00 00 00 00 02 6F 0A
					39 00 00 00 00 00 06 F6 70 70 70 70 70 //Power seq
					39 00 00 00 00 00 05 FF AA 55 A5 81
					39 00 00 00 00 00 02 6F 0D
					39 00 00 00 00 00 02 FB 80 // TE_opt
					39 00 00 00 00 00 06 F0 55 AA 52 08 01
					39 00 00 00 00 00 02 E5 00
					39 00 00 00 00 00 05 FF AA 55 A5 80
					39 00 00 00 00 00 02 6F 15
					39 00 00 00 00 00 03 F8 01 8C // DSPOSC=138.6MHz
					39 00 00 00 00 00 05 FF AA 55 A5 80
					39 00 00 00 00 00 02 6F 3E
					39 00 00 00 00 00 02 F8 00
					39 00 00 00 00 00 05 FF AA 55 A5 81
					39 00 00 00 00 00 02 6F 0B
					39 00 00 00 00 00 02 FD 04
					39 00 00 00 00 00 02 5A 01
					39 00 00 00 00 00 02 17 30
					39 00 00 00 00 00 03 5F 00 00
					39 00 00 00 00 00 02 35 00 // TE on
					39 00 00 00 00 00 0A 88 01 02 5F 09 4F 00 00 00 00
					39 00 00 00 00 00 02 53 20
					39 00 00 00 00 00 05 2A 00 00 04 BF
					39 00 00 00 00 00 05 2B 00 00 0A 4F
					39 00 00 00 00 00 02 90 03
					39 00 00 00 00 00 02 6F 01
					39 00 00 00 00 00 02 90 43
					39 00 00 00 00 00 13 91 AB A8 00 14 C2 00 02 31 02 05 00 08 05 0E 04 7B 10 E0 // VESA
					39 00 00 00 00 00 02 26 00
					39 00 00 00 00 00 02 6D 00
					39 00 00 00 00 00 02 6F 06
					39 00 00 00 00 00 02 6D 00
					// VFP/VBP SOP/GOP ON
					39 00 00 00 00 00 06 F0 55 AA 52 08 00
					15 00 00 00 00 00 02 6F 0D
					15 00 00 00 00 00 02 C2 0F
					//OSC：121.9-121.2 MHz
					39 00 00 00 00 00 05 FF AA 55 A5 80
					15 00 00 00 00 00 02 6F 31
					39 00 00 00 00 00 03 F8 01 B7
					// LFCC fix
					39 00 00 00 00 00 06 F0 55 AA 52 08 00
					15 00 00 00 00 00 02 6F 08
					15 00 00 00 00 00 02 B2 C0
					39 00 00 00 00 00 06 F0 55 AA 52 08 09
					//Comp_DBVPNTS0~5 = 423h,424h,48Ah,48Bh,4F0h,4F1h
					15 00 00 00 00 00 02 6F 01
					39 00 00 00 00 00 0A BD 44 23 24 44 8A 8B 44 F0 F1
					// Fixed TE
					15 00 00 00 00 00 02 5A 00
					15 00 00 00 00 00 02 6F 03
					15 00 00 00 00 00 02 5A 00
					39 00 00 00 00 00 03 44 00 00
					15 00 00 00 00 00 02 6F 04
					39 00 00 00 00 00 0D 44 00 00 00 00 00 00 00 00 00 00 00 00
					39 00 00 00 00 00 06 F0 55 AA 52 08 00
					15 00 00 00 00 00 02 BE 47
					// TEST TE
					39 00 00 00 00 00 06 F0 55 AA 52 08 00
					15 00 00 00 00 00 02 6F 01
					15 00 00 00 00 00 02 BE 54
					39 00 00 00 00 00 06 F0 55 AA 52 08 00
					15 00 00 00 00 00 02 6F 07
					39 00 00 00 00 00 06 B5 4E 2C 00 00 00 //Nor ELVSS 2.3V,ELVDD 4.8V
					15 00 00 00 00 00 02 6F 0C
					39 00 00 00 00 00 06 B5 4E 35 00 00 00 //AOD ELVSS 1.4V,ELVDD 4.8V
					//2F:30->6D:08 90Hz(Repeat 1 times) --> 90Hz
					39 00 00 00 00 00 06 F0 55 AA 52 08 00
					15 00 00 00 00 00 02 6F 03
					39 00 00 00 00 00 03 35 00 00
					15 00 00 00 00 00 02 6F 20
					39 00 00 00 00 00 09 BA 00 01 02 02 00 01 02 02
					15 00 00 00 00 00 02 6F 30
					39 00 00 00 00 00 09 BA 00 01 02 08 00 01 02 08
					15 00 00 00 00 00 02 6F 40
					39 00 00 00 00 00 09 BA 00 01 02 11 00 01 02 11
					15 00 00 00 00 00 02 6F 50
					39 00 00 00 00 00 09 BA 00 01 02 59 00 01 02 59
					15 00 00 00 00 00 02 2F 31
					15 00 00 00 00 00 02 6D 08 //90Hz
					// DC/PWM fix
					39 00 00 00 00 00 06 F0 55 AA 52 08 09
					15 00 00 00 00 00 02 6F 1C
					39 00 00 00 00 00 06 BD 98 89 84 02 15 //Comp0_R_Gray0~4_DBV1
					15 00 00 00 00 00 02 6F 21
					39 00 00 00 00 00 06 BD 98 89 84 02 15 //Comp0_R_Gray0~4_DBV2
					15 00 00 00 00 00 02 6F 26
					39 00 00 00 00 00 06 BD 12 09 04 86 97 //Comp0_R_Gray0~4_DBV3
					15 00 00 00 00 00 02 6F 2B
					39 00 00 00 00 00 06 BD 12 09 04 86 97 //Comp0_R_Gray0~4_DBV4
					15 00 00 00 00 00 02 6F 3A
					39 00 00 00 00 00 06 BD 98 89 84 02 15 //Comp0_G_Gray0~4_DBV1
					15 00 00 00 00 00 02 6F 3F
					39 00 00 00 00 00 06 BD 98 89 84 02 15 //Comp0_G_Gray0~4_DBV1
					15 00 00 00 00 00 02 6F 44
					39 00 00 00 00 00 06 BD 12 09 04 86 97 //Comp0_G_Gray0~4_DBV3
					15 00 00 00 00 00 02 6F 49
					39 00 00 00 00 00 06 BD 12 09 04 86 97 //Comp0_G_Gray0~4_DBV4
					15 00 00 00 00 00 02 6F 58
					39 00 00 00 00 00 06 BD 98 09 84 02 15 //Comp 0_B_Gray0~4_DBV1
					15 00 00 00 00 00 02 6F 5D
					39 00 00 00 00 00 06 BD 98 89 84 02 15 //Comp0_B_Gray0~4_DBV1
					15 00 00 00 00 00 02 6F 62
					39 00 00 00 00 00 06 BD 12 09 04 86 97 //Comp0_B_Gray0~4_DBV3
					15 00 00 00 00 00 02 6F 67
					39 00 00 00 00 00 06 BD 12 09 04 86 97 //Comp0_B_Gray0~4_DBV4
					// fix odc green ghosting
					39 00 00 00 00 00 06 F0 55 AA 52 08 08
					39 00 00 00 00 00 05 E0 21 01 01 01
					39 00 00 00 00 00 02 6F 35
					39 00 00 00 00 00 02 E2 00
					39 00 00 00 00 00 02 6F 43
					39 00 00 00 00 00 02 E2 00
					39 00 00 00 00 00 02 6F 51
					39 00 00 00 00 00 02 E2 00
					39 00 00 00 00 00 02 6F 5F
					39 00 00 00 00 00 02 E2 00
					39 00 00 00 00 00 02 6F 6D
					39 00 00 00 00 00 02 E2 00
					39 00 00 00 00 00 02 6F 7B
					39 00 00 00 00 00 02 E2 00
					// Demura LLC impro
					39 00 00 00 00 00 06 F0 55 AA 52 08 04
					39 00 00 00 00 00 08 E1 87 07 07 03 03 03 03
					15 00 00 00 00 00 02 6F 07
					39 00 00 00 00 00 05 03 01 01 01 01
					15 00 00 00 00 00 02 6F 0C
					39 00 00 00 00 00 08 E1 00 00 00 00 00 00 00
					15 00 00 00 00 00 02 6F 13
					39 00 00 00 00 00 05 00 00 00 00 00
					15 00 00 00 00 00 02 6F 18
					39 00 00 00 00 00 08 E1 07 07 07 03 03 03 03
					15 00 00 00 00 00 02 6F 1F
					39 00 00 00 00 00 05 03 01 01 01 01
					15 00 00 00 00 00 02 6F 24
					39 00 00 00 00 00 08 E1 01 03 15 1E 2E 3E 48
					15 00 00 00 00 00 02 6F 2B
					39 00 00 00 00 00 05 49 75 B1 DB FF
					// 3d lut inpro L240
					39 00 00 00 00 00 06 F0 55 AA 52 08 00
					39 00 00 00 00 00 02 6F 02
					39 00 00 00 00 00 07 E6 00 01 00 BC 01 5E
					39 00 00 00 00 00 02 6F 17
					39 00 00 00 00 00 02 E6 01
					39 00 00 00 00 00 06 F0 55 AA 52 08 00
					39 00 00 00 00 00 02 E6 80
					39 00 00 00 00 00 02 6F 00
					39 00 00 00 00 00 19 E7 00 00 00 00 00 00 00 00 00 00 00 00 00 00 00 00 00 00 00 00 00 00 00 00
					39 00 00 00 00 00 02 6F 18
					39 00 00 00 00 00 19 E7 00 40 40 40 40 40 40 40 40 40 40 40 40 40 40 40 40 40 40 40 40 40 40 40
					39 00 00 00 00 00 02 6F 30
					39 00 00 00 00 00 19 E7 40 40 80 80 80 80 80 80 80 80 80 80 80 80 80 80 80 80 80 80 80 80 80 80
					39 00 00 00 00 00 02 6F 48
					39 00 00 00 00 00 19 E7 80 80 80 C0 C0 C0 C0 C0 C0 C0 C0 C0 C0 C0 C0 C0 C0 C0 C0 C0 C0 C0 C0 C0
					39 00 00 00 00 00 02 6F 60
					39 00 00 00 00 00 19 E7 C0 C0 C0 C0 FF FF FF FF FF FF FF FF FF FF FF FF FF FF FF FF FF FF FF FF
					39 00 00 00 00 00 02 6F 78
					39 00 00 00 00 00 19 E7 FF FF FF FF FF 00 00 00 00 00 40 40 40 40 40 80 80 80 80 80 C0 C0 C0 C0
					39 00 00 00 00 00 02 6F 90
					39 00 00 00 00 00 19 E7 C0 FF FF FF FF FF 00 00 00 00 00 40 40 40 40 40 80 80 80 80 80 C0 C0 C0
					39 00 00 00 00 00 02 6F A8
					39 00 00 00 00 00 19 E7 C0 C0 FF FF FF FF FF 00 00 00 00 00 40 40 40 40 40 80 80 80 80 80 C0 C0
					39 00 00 00 00 00 02 6F C0
					39 00 00 00 00 00 19 E7 C0 C0 C0 FF FF FF FF FF 00 00 00 00 00 40 40 40 40 40 80 80 80 80 80 C0
					39 00 00 00 00 00 02 6F D8
					39 00 00 00 00 00 19 E7 C0 C0 C0 C0 FF FF FF FF FF 00 00 00 00 00 40 40 40 40 40 80 80 80 80 80
					39 00 00 00 00 00 02 6F 00
					39 00 00 00 00 00 19 E8 C0 C0 C0 C0 C0 FF FF FF FF FF 00 40 80 C0 FF 00 40 80 C0 FF 00 40 80 C0
					39 00 00 00 00 00 02 6F 18
					39 00 00 00 00 00 19 E8 FF 00 40 80 C0 FF 00 40 80 C0 FF 00 40 80 C0 FF 00 40 80 C0 FF 00 40 80
					39 00 00 00 00 00 02 6F 30
					39 00 00 00 00 00 19 E8 C0 FF 00 40 80 C0 FF 00 40 80 C0 FF 00 40 80 C0 FF 00 40 80 C0 FF 00 40
					39 00 00 00 00 00 02 6F 48
					39 00 00 00 00 00 19 E8 80 C0 FF 00 40 80 C0 FF 00 40 80 C0 FF 00 40 80 C0 FF 00 40 80 C0 FF 00
					39 00 00 00 00 00 02 6F 60
					39 00 00 00 00 00 19 E8 40 80 C0 FF 00 40 80 C0 FF 00 40 80 C0 FF 00 40 80 C0 FF 00 40 80 C0 FF
					39 00 00 00 00 00 02 6F 78
					39 00 00 00 00 00 19 E8 00 40 80 C0 FF 00 40 80 C0 FF 00 40 80 C0 FF 08 10 18 20 28 30 38 48 50
					39 00 00 00 00 00 02 6F 90
					39 00 00 00 00 00 19 E8 58 60 68 70 78 88 90 98 A0 A8 B0 B8 C8 D0 D8 E0 E8 F0 F8 08 10 18 20 28
					39 00 00 00 00 00 02 6F A8
					39 00 00 00 00 00 19 E8 30 38 48 50 58 60 68 70 78 88 90 98 A0 A8 B0 B8 C8 D0 D8 E0 E8 F0 F8 08
					39 00 00 00 00 00 02 6F C0
					39 00 00 00 00 00 19 E8 10 18 20 28 30 38 48 50 58 60 68 70 78 88 90 98 A0 A8 B0 B8 C8 D0 D8 E0
					39 00 00 00 00 00 02 6F D8
					39 00 00 00 00 00 19 E8 E8 F0 F8 10 10 00 20 10 10 10 00 10 10 20 10 00 10 10 10 10 20 00 00 00
					39 00 00 00 00 00 02 E6 00
					39 00 00 00 00 00 06 F0 55 AA 52 08 00
					39 00 00 00 00 00 02 E6 81
					39 00 00 00 00 00 02 6F 00
					39 00 00 00 00 00 19 E7 00 00 00 00 00 00 00 00 00 00 00 00 00 00 00 00 00 00 00 00 00 00 00 00
					39 00 00 00 00 00 02 6F 18
					39 00 00 00 00 00 19 E7 00 40 40 40 40 40 40 40 40 40 40 40 40 40 40 40 40 40 40 40 40 40 40 40
					39 00 00 00 00 00 02 6F 30
					39 00 00 00 00 00 19 E7 40 40 80 80 80 80 80 80 80 80 80 80 80 80 80 80 80 80 80 80 80 80 80 80
					39 00 00 00 00 00 02 6F 48
					39 00 00 00 00 00 19 E7 80 80 80 C0 C0 C0 C0 C0 C0 C0 C0 C0 C0 C0 C0 C0 C0 C0 C0 C0 C0 C0 C0 C0
					39 00 00 00 00 00 02 6F 60
					39 00 00 00 00 00 19 E7 C0 C0 C0 C0 FF FF FF FF FF FF FF FF FF FF FF FF FF FF FF FF FF FF FF FF
					39 00 00 00 00 00 02 6F 78
					39 00 00 00 00 00 19 E7 FF FF FF FF FF 00 00 00 00 00 40 40 40 40 40 80 80 80 80 80 C0 C0 C0 C0
					39 00 00 00 00 00 02 6F 90
					39 00 00 00 00 00 19 E7 C0 FF FF FF FF FF 00 00 00 00 00 40 40 40 40 40 80 80 80 80 80 C0 C0 C0
					39 00 00 00 00 00 02 6F A8
					39 00 00 00 00 00 19 E7 C0 C0 FF FF FF FF FF 00 00 00 00 00 40 40 40 40 40 80 80 80 80 80 C0 C0
					39 00 00 00 00 00 02 6F C0
					39 00 00 00 00 00 19 E7 C0 C0 C0 FF FF FF FF FF 00 00 00 00 00 40 40 40 40 40 80 80 80 80 80 C0
					39 00 00 00 00 00 02 6F D8
					39 00 00 00 00 00 19 E7 C0 C0 C0 C0 FF FF FF FF FF 00 00 00 00 00 40 40 40 40 40 80 80 80 80 80
					39 00 00 00 00 00 02 6F 00
					39 00 00 00 00 00 19 E8 C0 C0 C0 C0 C0 FF FF FF FF FF 00 40 80 C0 FF 00 40 80 C0 FF 00 40 80 C0
					39 00 00 00 00 00 02 6F 18
					39 00 00 00 00 00 19 E8 FF 00 40 80 C0 FF 00 40 80 C0 FF 00 40 80 C0 FF 00 40 80 C0 FF 00 40 80
					39 00 00 00 00 00 02 6F 30
					39 00 00 00 00 00 19 E8 C0 FF 00 40 80 C0 FF 00 40 80 C0 FF 00 40 80 C0 FF 00 40 80 C0 FF 00 40
					39 00 00 00 00 00 02 6F 48
					39 00 00 00 00 00 19 E8 80 C0 FF 00 40 80 C0 FF 00 40 80 C0 FF 00 40 80 C0 FF 00 40 80 C0 FF 00
					39 00 00 00 00 00 02 6F 60
					39 00 00 00 00 00 19 E8 40 80 C0 FF 00 40 80 C0 FF 00 40 80 C0 FF 00 40 80 C0 FF 00 40 80 C0 FF
					39 00 00 00 00 00 02 6F 78
					39 00 00 00 00 00 19 E8 00 40 80 C0 FF 00 40 80 C0 FF 00 40 80 C0 FF 08 10 18 20 28 30 38 48 50
					39 00 00 00 00 00 02 6F 90
					39 00 00 00 00 00 19 E8 58 60 68 70 78 86 8E 95 9D A5 AE B7 C8 D0 D8 E0 E8 F0 F8 08 10 18 20 28
					39 00 00 00 00 00 02 6F A8
					39 00 00 00 00 00 19 E8 30 38 48 50 58 60 68 70 78 88 90 98 A0 A8 B0 B8 C6 CD D4 DC E5 EE F8 08
					39 00 00 00 00 00 02 6F C0
					39 00 00 00 00 00 19 E8 10 18 20 28 30 38 48 50 58 60 68 70 78 88 90 98 A0 A8 B0 B8 C8 D0 D8 E0
					39 00 00 00 00 00 02 6F D8
					39 00 00 00 00 00 19 E8 E8 F0 F8 10 10 00 20 10 10 10 00 10 10 20 10 00 10 10 10 10 20 00 00 00
					39 00 00 00 00 00 02 E6 00
					39 00 00 00 00 00 06 F0 55 AA 52 08 00
					39 00 00 00 00 00 02 E6 82
					39 00 00 00 00 00 02 6F 00
					39 00 00 00 00 00 19 E7 00 00 00 00 00 00 00 00 00 00 00 00 00 00 00 00 00 00 00 00 00 00 00 00
					39 00 00 00 00 00 02 6F 18
					39 00 00 00 00 00 19 E7 00 40 40 40 40 40 40 40 40 40 40 40 40 40 40 40 40 40 40 40 40 40 40 40
					39 00 00 00 00 00 02 6F 30
					39 00 00 00 00 00 19 E7 40 40 80 80 80 80 80 80 80 80 80 80 80 80 80 80 80 80 80 80 80 80 80 80
					39 00 00 00 00 00 02 6F 48
					39 00 00 00 00 00 19 E7 80 80 80 C0 C0 C0 C0 C0 C0 C0 C0 C0 C0 C0 C0 C0 C0 C0 C0 C0 C0 C0 C0 C0
					39 00 00 00 00 00 02 6F 60
					39 00 00 00 00 00 19 E7 C0 C0 C0 C0 FF FF FF FF FF FF FF FF FF FF FF FF FF FF FF FF FF FF FF FF
					39 00 00 00 00 00 02 6F 78
					39 00 00 00 00 00 19 E7 FF FF FF FF FF 00 00 00 00 00 40 40 40 40 40 80 80 80 80 80 C0 C0 C0 C0
					39 00 00 00 00 00 02 6F 90
					39 00 00 00 00 00 19 E7 C0 FF FF FF FF FF 00 00 00 00 00 40 40 40 40 40 80 80 80 80 80 C0 C0 C0
					39 00 00 00 00 00 02 6F A8
					39 00 00 00 00 00 19 E7 C0 C0 FF FF FF FF FF 00 00 00 00 00 40 40 40 40 40 80 80 80 80 80 C0 C0
					39 00 00 00 00 00 02 6F C0
					39 00 00 00 00 00 19 E7 C0 C0 C0 FF FF FF FF FF 00 00 00 00 00 40 40 40 40 40 80 80 80 80 80 C0
					39 00 00 00 00 00 02 6F D8
					39 00 00 00 00 00 19 E7 C0 C0 C0 C0 FF FF FF FF FF 00 00 00 00 00 40 40 40 40 40 80 80 80 80 80
					39 00 00 00 00 00 02 6F 00
					39 00 00 00 00 00 19 E8 C0 C0 C0 C0 C0 FF FF FF FF FF 00 40 80 C0 FF 00 40 80 C0 FF 00 40 80 C0
					39 00 00 00 00 00 02 6F 18
					39 00 00 00 00 00 19 E8 FF 00 40 80 C0 FF 00 40 80 C0 FF 00 40 80 C0 FF 00 40 80 C0 FF 00 40 80
					39 00 00 00 00 00 02 6F 30
					39 00 00 00 00 00 19 E8 C0 FF 00 40 80 C0 FF 00 40 80 C0 FF 00 40 80 C0 FF 00 40 80 C0 FF 00 40
					39 00 00 00 00 00 02 6F 48
					39 00 00 00 00 00 19 E8 80 C0 FF 00 40 80 C0 FF 00 40 80 C0 FF 00 40 80 C0 FF 00 40 80 C0 FF 00
					39 00 00 00 00 00 02 6F 60
					39 00 00 00 00 00 19 E8 40 80 C0 FF 00 40 80 C0 FF 00 40 80 C0 FF 00 40 80 C0 FF 00 40 80 C0 FF
					39 00 00 00 00 00 02 6F 78
					39 00 00 00 00 00 19 E8 00 40 80 C0 FF 00 40 80 C0 FF 00 40 80 C0 FF 08 10 18 20 28 30 38 48 50
					39 00 00 00 00 00 02 6F 90
					39 00 00 00 00 00 19 E8 58 60 68 70 78 88 90 98 A0 A8 B0 B8 C8 D0 D8 E0 E8 F0 F8 08 10 18 20 28
					39 00 00 00 00 00 02 6F A8
					39 00 00 00 00 00 19 E8 30 38 48 50 58 60 68 70 78 88 90 98 A0 A8 B0 B8 C8 D0 D8 E0 E8 F0 F8 08
					39 00 00 00 00 00 02 6F C0
					39 00 00 00 00 00 19 E8 10 18 20 28 30 38 48 50 58 60 68 70 78 88 90 98 A0 A8 B0 B8 C8 D0 D8 E0
					39 00 00 00 00 00 02 6F D8
					39 00 00 00 00 00 19 E8 E8 F0 F8 10 10 00 20 10 10 10 00 10 10 20 10 00 10 10 10 10 20 00 00 00
					39 00 00 00 00 00 02 E6 00
					39 00 00 00 00 00 02 57 80
					//osc fixed
					39 00 00 00 00 00 06 F0 55 AA 52 08 01
					39 00 00 00 00 00 06 C3 DD 06 20 11 FF
					15 00 00 00 00 00 02 6F 05
					39 00 00 00 00 00 06 C3 00 06 20 11 FF
					15 00 00 00 00 00 02 6F 0A
					39 00 00 00 00 00 06 C3 00 07 0E 20 06
					15 00 00 00 00 00 02 6F 0F
					39 00 00 00 00 00 06 C3 44 19 07 11 18
					15 00 00 00 00 00 02 6F 14
					39 00 00 00 00 00 06 C3 06 5C 13 07 0E
					15 00 00 00 00 00 02 6F 19
					39 00 00 00 00 00 06 C3 20 06 44 19 07
					15 00 00 00 00 00 02 6F 1E
					39 00 00 00 00 00 06 C3 0E 20 06 44 19
					15 00 00 00 00 00 02 6F 23
					39 00 00 00 00 00 06 C3 07 0E 20 06 44
					15 00 00 00 00 00 02 6F 28
					15 00 00 00 00 00 02 C3 19
					//Modify power-off timing
					39 00 00 00 00 00 06 F0 55 AA 52 08 03
					15 00 00 00 00 00 02 6F 07
					15 00 00 00 00 00 02 C6 48
					//Light On
					39 00 00 00 78 00 01 11 // Sleep out
					39 00 00 00 00 00 01 29 // Display out
				];
				oplus,dsi-aod-off-command = [
					39 00 00 40 00 00 06 F0 55 AA 52 08 00
					39 00 00 40 00 00 02 2F 31
					39 00 00 40 00 00 02 6F 03
					39 00 00 40 00 00 03 35 00 00
					39 00 00 40 00 00 02 38 00
					05 00 00 40 00 00 01 2C
					39 00 00 40 00 00 03 51 00 00
					39 00 00 40 00 00 06 F0 55 AA 52 08 08
					39 00 00 40 00 00 02 BE 03
					39 00 00 40 00 00 05 FF AA 55 A5 81
					39 00 00 40 00 00 02 6F 0B
					39 00 00 00 00 00 02 FD 04 //gmaconv on
				];
				oplus,dsi-panel-aod-off-insert-black-command = [
					39 00 00 40 00 00 06 F0 55 AA 52 08 00
					39 00 00 40 00 00 02 2F 31
					39 00 00 40 00 00 02 6F 03
					39 00 00 40 00 00 03 35 00 00
					39 00 00 40 00 00 02 38 00
					39 00 00 40 00 00 03 51 00 00
					39 00 00 40 00 00 06 F0 55 AA 52 08 08
					39 00 00 40 00 00 02 BE 03
					39 00 00 40 00 00 05 FF AA 55 A5 81
					39 00 00 40 00 00 02 6F 0B
					39 00 00 00 00 00 02 FD 04 //gmaconv on
				];
				oplus,dsi-ultra-low-power-aod-on-command = [
					39 00 00 40 00 00 06 F0 55 AA 52 08 00
					39 00 00 40 00 00 02 6F 18
					39 00 00 00 00 00 06 BB 01 00 02 02 00
				];
				oplus,dsi-ultra-low-power-aod-off-command = [
					39 00 00 40 00 00 06 F0 55 AA 52 08 00
					39 00 00 40 00 00 02 6F 18
					39 00 00 00 00 00 06 BB 01 00 00 00 00
				];
				oplus,dsi-hbm-on-command = [
					39 00 00 00 00 00 03 51 0F FE
				];
				oplus,dsi-hbm-off-command = [
					39 00 00 00 00 00 03 51 0D BB
				];
				oplus,dsi-adfr-min-fps-90hz-command = [
					39 00 00 40 00 00 06 F0 55 AA 52 08 09
					15 00 00 40 00 00 02 6F 1C
					39 00 00 40 00 00 06 BD 98 89 84 02 15
					15 00 00 40 00 00 02 6F 21
					39 00 00 40 00 00 06 BD 98 89 84 02 15
					15 00 00 40 00 00 02 6F 26
					39 00 00 40 00 00 06 BD 12 09 04 86 97
					15 00 00 40 00 00 02 6F 2B
					39 00 00 40 00 00 06 BD 12 09 04 86 97
					15 00 00 40 00 00 02 6F 3A
					39 00 00 40 00 00 06 BD 98 89 84 02 15
					15 00 00 40 00 00 02 6F 3F
					39 00 00 40 00 00 06 BD 98 89 84 02 15
					15 00 00 40 00 00 02 6F 44
					39 00 00 40 00 00 06 BD 12 09 04 86 97
					15 00 00 40 00 00 02 6F 49
					39 00 00 40 00 00 06 BD 12 09 04 86 97
					15 00 00 40 00 00 02 6F 58
					39 00 00 40 00 00 06 BD 98 89 84 02 15
					15 00 00 40 00 00 02 6F 5D
					39 00 00 40 00 00 06 BD 98 89 84 02 15
					15 00 00 40 00 00 02 6F 62
					39 00 00 40 00 00 06 BD 12 09 04 86 97
					15 00 00 40 00 00 02 6F 67
					39 00 00 40 00 00 06 BD 12 09 04 86 97
					39 00 00 40 00 00 02 2F 31
					39 00 00 00 00 00 02 6D 08
				];
				oplus,dsi-adfr-min-fps-30hz-command = [
					39 00 00 40 00 00 06 F0 55 AA 52 08 09
					15 00 00 40 00 00 02 6F 1C
					39 00 00 40 00 00 06 BD 98 89 84 02 15
					15 00 00 40 00 00 02 6F 21
					39 00 00 40 00 00 06 BD 98 89 84 02 15
					15 00 00 40 00 00 02 6F 26
					39 00 00 40 00 00 06 BD 12 09 04 86 97
					15 00 00 40 00 00 02 6F 2B
					39 00 00 40 00 00 06 BD 12 09 04 86 97
					15 00 00 40 00 00 02 6F 3A
					39 00 00 40 00 00 06 BD 98 89 84 02 15
					15 00 00 40 00 00 02 6F 3F
					39 00 00 40 00 00 06 BD 98 89 84 02 15
					15 00 00 40 00 00 02 6F 44
					39 00 00 40 00 00 06 BD 12 09 04 86 97
					15 00 00 40 00 00 02 6F 49
					39 00 00 40 00 00 06 BD 12 09 04 86 97
					15 00 00 40 00 00 02 6F 58
					39 00 00 40 00 00 06 BD 98 89 84 02 15
					15 00 00 40 00 00 02 6F 5D
					39 00 00 40 00 00 06 BD 98 89 84 02 15
					15 00 00 40 00 00 02 6F 62
					39 00 00 40 00 00 06 BD 12 09 04 86 97
					15 00 00 40 00 00 02 6F 67
					39 00 00 40 00 00 06 BD 12 09 04 86 97
					39 00 00 40 00 00 02 2F 31
					39 00 00 00 00 00 02 6D 0A
				];
				oplus,dsi-adfr-min-fps-10hz-command = [
					39 00 00 40 00 00 06 F0 55 AA 52 08 09
					15 00 00 40 00 00 02 6F 1C
					39 00 00 40 00 00 06 BD 98 89 84 02 15
					15 00 00 40 00 00 02 6F 21
					39 00 00 40 00 00 06 BD 98 89 84 02 15
					15 00 00 40 00 00 02 6F 26
					39 00 00 40 00 00 06 BD 12 09 04 86 97
					15 00 00 40 00 00 02 6F 2B
					39 00 00 40 00 00 06 BD 12 09 04 86 97
					15 00 00 40 00 00 02 6F 3A
					39 00 00 40 00 00 06 BD 98 89 84 02 15
					15 00 00 40 00 00 02 6F 3F
					39 00 00 40 00 00 06 BD 98 89 84 02 15
					15 00 00 40 00 00 02 6F 44
					39 00 00 40 00 00 06 BD 12 09 04 86 97
					15 00 00 40 00 00 02 6F 49
					39 00 00 40 00 00 06 BD 12 09 04 86 97
					15 00 00 40 00 00 02 6F 58
					39 00 00 40 00 00 06 BD 98 89 84 02 15
					15 00 00 40 00 00 02 6F 5D
					39 00 00 40 00 00 06 BD 98 89 84 02 15
					15 00 00 40 00 00 02 6F 62
					39 00 00 40 00 00 06 BD 12 09 04 86 97
					15 00 00 40 00 00 02 6F 67
					39 00 00 40 00 00 06 BD 12 09 04 86 97
					39 00 00 40 00 00 02 2F 31
					39 00 00 00 00 00 02 6D 0C
				];
				oplus,dsi-adfr-min-fps-1hz-command = [
					39 00 00 40 00 00 06 F0 55 AA 52 08 09
					15 00 00 40 00 00 02 6F 1C
					39 00 00 40 00 00 06 BD 98 89 84 02 15
					15 00 00 40 00 00 02 6F 21
					39 00 00 40 00 00 06 BD 98 89 84 02 15
					15 00 00 40 00 00 02 6F 26
					39 00 00 40 00 00 06 BD 12 09 04 86 97
					15 00 00 40 00 00 02 6F 2B
					39 00 00 40 00 00 06 BD 12 09 04 86 97
					15 00 00 40 00 00 02 6F 3A
					39 00 00 40 00 00 06 BD 98 89 84 02 15
					15 00 00 40 00 00 02 6F 3F
					39 00 00 40 00 00 06 BD 98 89 84 02 15
					15 00 00 40 00 00 02 6F 44
					39 00 00 40 00 00 06 BD 12 09 04 86 97
					15 00 00 40 00 00 02 6F 49
					39 00 00 40 00 00 06 BD 12 09 04 86 97
					15 00 00 40 00 00 02 6F 58
					39 00 00 40 00 00 06 BD 98 89 84 02 15
					15 00 00 40 00 00 02 6F 5D
					39 00 00 40 00 00 06 BD 98 89 84 02 15
					15 00 00 40 00 00 02 6F 62
					39 00 00 40 00 00 06 BD 12 09 04 86 97
					15 00 00 40 00 00 02 6F 67
					39 00 00 40 00 00 06 BD 12 09 04 86 97
					39 00 00 40 00 00 02 2F 31
					39 00 00 00 00 00 02 6D 0E
				];
				oplus,dsi-timing-switch-command-state = "dsi_hs_mode";
				oplus,dsi-on-command-state = "dsi_lp_mode";
				oplus,dsi-aod-off-command-state = "dsi_ls_mode";
				oplus,dsi-panel-aod-off-insert-black-command-state = "dsi_ls_mode";
				oplus,dsi-ultra-low-power-aod-on-command-state = "dsi_ls_mode";
				oplus,dsi-ultra-low-power-aod-off-command-state = "dsi_ls_mode";
				oplus,dsi-hbm-on-command-state = "dsi_hs_mode";
				oplus,dsi-hbm-off-command-state = "dsi_hs_mode";
				oplus,dsi-adfr-min-fps-90hz-command-state = "dsi_hs_mode";
				oplus,dsi-adfr-min-fps-30hz-command-state = "dsi_hs_mode";
				oplus,dsi-adfr-min-fps-10hz-command-state = "dsi_hs_mode";
				oplus,dsi-adfr-min-fps-1hz-command-state = "dsi_hs_mode";
				oplus,dsc-params-entries = <&dsc_params>;
				oplus,spr-params-entries = <&spr_params>;
				oplus,dyn-fps {
					switch_en = <1>;
					vact_timing_fps = <90>;
					apollo_limit_superior_us = <7880>;
					apollo_limit_inferior_us = <10000>;
					apollo_transfer_time_us = <8800>;
				};
				oplus,display-mode {
					display-mode@0 {
						hdisplay = <1216>;
						vdisplay = <2640>;
						fhd-hfp = <2>;
						fhd-hsa = <26>;
						fhd-hbp = <36>;
						fhd-vfp = <100>;
						fhd-vsa = <8>;
						fhd-vbp = <76>;
						hskew = <STANDARD_ADFR>;
					};
					display-mode@1 {
						hdisplay = <1080>;
						vdisplay = <2344>;
						fhd-hfp = <2>;
						fhd-hsa = <26>;
						fhd-hbp = <36>;
						fhd-vfp = <100>;
						fhd-vsa = <8>;
						fhd-vbp = <76>;
						hskew = <STANDARD_ADFR>;
					};
				};
			};
			timing@sa_fhd_120 {
				cell-index = <2>;
				oplus,dsi-panel-framerate = <120>;
				oplus,dsi-panel-pllclk = <553>;
				oplus,cmd-null-pkt-en = <0>;
				oplus,cmd-null-pkt-len = <0>;
				oplus,merge-trig-offset = <333>;
				oplus,ofp-aod-off-setbacklight-delay = <4>;
				#include "panel-ac247-p-7-a0014-dsi-cmd-common.dtsi"
				oplus,dsi-timing-switch-command = [
					//120HZ
					39 00 00 40 00 00 06 F0 55 AA 52 08 00
					15 00 00 40 00 00 02 6F 03
					39 00 00 40 00 00 03 35 00 00
					15 00 00 40 00 00 02 6F 20
					39 00 00 40 00 00 09 BA 00 01 03 03 00 01 03 03
					15 00 00 40 00 00 02 6F 30
					39 00 00 40 00 00 09 BA 00 01 03 0B 00 01 03 0B
					15 00 00 40 00 00 02 6F 40
					39 00 00 40 00 00 09 BA 00 01 03 17 00 01 03 17
					15 00 00 40 00 00 02 6F 50
					39 00 00 40 00 00 09 BA 00 01 03 77 00 01 03 77
					15 00 00 40 00 00 02 2F 30
					15 00 00 40 00 00 02 6D 00 //120Hz
					// DC/PWM fix
					39 00 00 40 00 00 06 F0 55 AA 52 08 09
					15 00 00 40 00 00 02 6F 1C
					39 00 00 40 00 00 06 BD A0 89 84 02 15 //Comp0_R_Gray0~4_DBV1
					15 00 00 40 00 00 02 6F 21
					39 00 00 40 00 00 06 BD A0 89 84 02 15 //Comp0_R_Gray0~4_DBV2
					15 00 00 40 00 00 02 6F 26
					39 00 00 40 00 00 06 BD 14 09 04 86 97 //Comp0_R_Gray0~4_DBV3
					15 00 00 40 00 00 02 6F 2B
					39 00 00 40 00 00 06 BD 14 09 04 86 97 //Comp0_R_Gray0~4_DBV4
					15 00 00 40 00 00 02 6F 3A
					39 00 00 40 00 00 06 BD A0 89 84 02 15 //Comp0_G_Gray0~4_DBV1
					15 00 00 40 00 00 02 6F 3F
					39 00 00 40 00 00 06 BD A0 89 84 02 15 //Comp0_G_Gray0~4_DBV1
					15 00 00 40 00 00 02 6F 44
					39 00 00 40 00 00 06 BD 14 09 04 86 97 //Comp0_G_Gray0~4_DBV3
					15 00 00 40 00 00 02 6F 49
					39 00 00 40 00 00 06 BD 14 09 04 86 97 //Comp0_G_Gray0~4_DBV4
					15 00 00 40 00 00 02 6F 58
					39 00 00 40 00 00 06 BD A0 89 84 02 15 //Comp0_B_Gray0~4_DBV1
					15 00 00 40 00 00 02 6F 5D
					39 00 00 40 00 00 06 BD A0 89 84 02 15 //Comp0_B_Gray0~4_DBV1
					15 00 00 40 00 00 02 6F 62
					39 00 00 40 00 00 06 BD 14 09 04 86 97 //Comp0_B_Gray0~4_DBV3
					15 00 00 40 00 00 02 6F 67
					39 00 00 00 00 00 06 BD 14 09 04 86 97 //Comp0_B_Gray0~4_DBV4
				];
				oplus,dsi-on-command = [
					// init code
					39 00 00 00 00 00 05 FF AA 55 A5 81
					39 00 00 00 00 00 02 6F 0C
					39 00 00 00 00 00 02 FD 08
					39 00 00 00 00 00 02 6F 02
					39 00 00 00 00 00 02 F9 84
					39 00 00 00 00 00 02 6F 10
					39 00 00 00 00 00 02 FB 40
					39 00 00 00 00 00 05 FF AA 55 A5 80
					39 00 00 00 00 00 02 6F 48
					39 00 00 00 00 00 02 F2 00
					39 00 00 00 00 00 05 FF AA 55 A5 80
					39 00 00 00 00 00 02 6F 16
					39 00 00 00 00 00 03 F4 02 74
					39 00 00 00 00 00 05 FF AA 55 A5 80
					39 00 00 00 00 00 02 6F 42
					39 00 00 00 00 00 02 F4 00
					39 00 00 00 00 00 05 FF AA 55 A5 80
					39 00 00 00 00 00 02 6F 49
					39 00 00 00 00 00 02 F2 10
					39 00 00 00 00 00 05 FF AA 55 A5 81
					39 00 00 00 00 00 02 6F 05
					39 00 00 00 00 00 03 FE 3C 3C
					39 00 00 00 00 00 05 FF AA 55 A5 82
					39 00 00 00 00 00 02 6F 09
					39 00 00 00 00 00 02 F2 FF
					39 00 00 00 00 00 05 FF AA 55 A5 80
					39 00 00 00 00 00 02 6F 04
					39 00 00 00 00 00 02 F2 3C
					39 00 00 00 00 00 05 FF AA 55 A5 80
					39 00 00 00 00 00 02 6F 0A
					39 00 00 00 00 00 06 F6 70 70 70 70 70 //Power seq
					39 00 00 00 00 00 05 FF AA 55 A5 81
					39 00 00 00 00 00 02 6F 0D
					39 00 00 00 00 00 02 FB 80 // TE_opt
					39 00 00 00 00 00 06 F0 55 AA 52 08 01
					39 00 00 00 00 00 02 E5 00
					39 00 00 00 00 00 05 FF AA 55 A5 80
					39 00 00 00 00 00 02 6F 15
					39 00 00 00 00 00 03 F8 01 8C // DSPOSC=138.6MHz
					39 00 00 00 00 00 05 FF AA 55 A5 80
					39 00 00 00 00 00 02 6F 3E
					39 00 00 00 00 00 02 F8 00
					39 00 00 00 00 00 05 FF AA 55 A5 81
					39 00 00 00 00 00 02 6F 0B
					39 00 00 00 00 00 02 FD 04
					39 00 00 00 00 00 02 5A 01
					39 00 00 00 00 00 02 17 30
					39 00 00 00 00 00 03 5F 00 00
					39 00 00 00 00 00 02 35 00 // TE on
					39 00 00 00 00 00 0A 88 01 02 5F 09 4F 00 00 00 00
					39 00 00 00 00 00 02 53 20
					39 00 00 00 00 00 05 2A 00 00 04 BF
					39 00 00 00 00 00 05 2B 00 00 0A 4F
					39 00 00 00 00 00 02 90 03
					39 00 00 00 00 00 02 6F 01
					39 00 00 00 00 00 02 90 43
					39 00 00 00 00 00 13 91 AB A8 00 14 C2 00 02 31 02 05 00 08 05 0E 04 7B 10 E0 // VESA
					39 00 00 00 00 00 02 26 00
					39 00 00 00 00 00 02 6D 00
					39 00 00 00 00 00 02 6F 06
					39 00 00 00 00 00 02 6D 00
					// VFP/VBP SOP/GOP ON
					39 00 00 00 00 00 06 F0 55 AA 52 08 00
					15 00 00 00 00 00 02 6F 0D
					15 00 00 00 00 00 02 C2 0F
					//OSC：121.9-121.2 MHz
					39 00 00 00 00 00 05 FF AA 55 A5 80
					15 00 00 00 00 00 02 6F 31
					39 00 00 00 00 00 03 F8 01 B7
					// LFCC fix
					39 00 00 00 00 00 06 F0 55 AA 52 08 00
					15 00 00 00 00 00 02 6F 08
					15 00 00 00 00 00 02 B2 C0
					39 00 00 00 00 00 06 F0 55 AA 52 08 09
					//Comp_DBVPNTS0~5 = 423h,424h,48Ah,48Bh,4F0h,4F1h
					15 00 00 00 00 00 02 6F 01
					39 00 00 00 00 00 0A BD 44 23 24 44 8A 8B 44 F0 F1
					// Fixed TE
					15 00 00 00 00 00 02 5A 00
					15 00 00 00 00 00 02 6F 03
					15 00 00 00 00 00 02 5A 00
					39 00 00 00 00 00 03 44 00 00
					15 00 00 00 00 00 02 6F 04
					39 00 00 00 00 00 0D 44 00 00 00 00 00 00 00 00 00 00 00 00
					39 00 00 00 00 00 06 F0 55 AA 52 08 00
					15 00 00 00 00 00 02 BE 47
					// TEST TE
					39 00 00 00 00 00 06 F0 55 AA 52 08 00
					15 00 00 00 00 00 02 6F 01
					15 00 00 00 00 00 02 BE 54
					39 00 00 00 00 00 06 F0 55 AA 52 08 00
					15 00 00 00 00 00 02 6F 07
					39 00 00 00 00 00 06 B5 4E 2C 00 00 00 //Nor ELVSS 2.3V,ELVDD 4.8V
					15 00 00 00 00 00 02 6F 0C
					39 00 00 00 00 00 06 B5 4E 35 00 00 00 //AOD ELVSS 1.4V,ELVDD 4.8V
					//2F:30->6D:00 120Hz(Repeat 1 times) --> 120Hz
					39 00 00 00 00 00 06 F0 55 AA 52 08 00
					15 00 00 00 00 00 02 6F 03
					39 00 00 00 00 00 03 35 00 00
					15 00 00 00 00 00 02 6F 20
					39 00 00 00 00 00 09 BA 00 01 03 03 00 01 03 03
					15 00 00 00 00 00 02 6F 30
					39 00 00 00 00 00 09 BA 00 01 03 0B 00 01 03 0B
					15 00 00 00 00 00 02 6F 40
					39 00 00 00 00 00 09 BA 00 01 03 17 00 01 03 17
					15 00 00 00 00 00 02 6F 50
					39 00 00 00 00 00 09 BA 00 01 03 77 00 01 03 77
					15 00 00 00 00 00 02 2F 30
					15 00 00 00 00 00 02 6D 00 //120Hz
					// DC/PWM fix
					39 00 00 00 00 00 06 F0 55 AA 52 08 09
					15 00 00 00 00 00 02 6F 1C
					39 00 00 00 00 00 06 BD A0 89 84 02 15 //Comp0_R_Gray0~4_DBV1
					15 00 00 00 00 00 02 6F 21
					39 00 00 00 00 00 06 BD A0 89 84 02 15 //Comp0_R_Gray0~4_DBV2
					15 00 00 00 00 00 02 6F 26
					39 00 00 00 00 00 06 BD 14 09 04 86 97 //Comp0_R_Gray0~4_DBV3
					15 00 00 00 00 00 02 6F 2B
					39 00 00 00 00 00 06 BD 14 09 04 86 97 //Comp0_R_Gray0~4_DBV4
					15 00 00 00 00 00 02 6F 3A
					39 00 00 00 00 00 06 BD A0 89 84 02 15 //Comp0_G_Gray0~4_DBV1
					15 00 00 00 00 00 02 6F 3F
					39 00 00 00 00 00 06 BD A0 89 84 02 15 //Comp0_G_Gray0~4_DBV1
					15 00 00 00 00 00 02 6F 44
					39 00 00 00 00 00 06 BD 14 09 04 86 97 //Comp0_G_Gray0~4_DBV3
					15 00 00 00 00 00 02 6F 49
					39 00 00 00 00 00 06 BD 14 09 04 86 97 //Comp0_G_Gray0~4_DBV4
					15 00 00 00 00 00 02 6F 58
					39 00 00 00 00 00 06 BD A0 89 84 02 15 //Comp0_B_Gray0~4_DBV1
					15 00 00 00 00 00 02 6F 5D
					39 00 00 00 00 00 06 BD A0 89 84 02 15 //Comp0_B_Gray0~4_DBV1
					15 00 00 00 00 00 02 6F 62
					39 00 00 00 00 00 06 BD 04 09 04 86 97 //Comp0_B_Gray0~4_DBV3
					15 00 00 00 00 00 02 6F 67
					39 00 00 00 00 00 06 BD 14 09 04 86 97 //Comp0_B_Gray0~4_DBV4
					// fix odc green ghosting
					39 00 00 00 00 00 06 F0 55 AA 52 08 08
					39 00 00 00 00 00 05 E0 21 01 01 01
					39 00 00 00 00 00 02 6F 35
					39 00 00 00 00 00 02 E2 00
					39 00 00 00 00 00 02 6F 43
					39 00 00 00 00 00 02 E2 00
					39 00 00 00 00 00 02 6F 51
					39 00 00 00 00 00 02 E2 00
					39 00 00 00 00 00 02 6F 5F
					39 00 00 00 00 00 02 E2 00
					39 00 00 00 00 00 02 6F 6D
					39 00 00 00 00 00 02 E2 00
					39 00 00 00 00 00 02 6F 7B
					39 00 00 00 00 00 02 E2 00
					// Demura LLC impro
					39 00 00 00 00 00 06 F0 55 AA 52 08 04
					39 00 00 00 00 00 08 E1 87 07 07 03 03 03 03
					15 00 00 00 00 00 02 6F 07
					39 00 00 00 00 00 05 03 01 01 01 01
					15 00 00 00 00 00 02 6F 0C
					39 00 00 00 00 00 08 E1 00 00 00 00 00 00 00
					15 00 00 00 00 00 02 6F 13
					39 00 00 00 00 00 05 00 00 00 00 00
					15 00 00 00 00 00 02 6F 18
					39 00 00 00 00 00 08 E1 07 07 07 03 03 03 03
					15 00 00 00 00 00 02 6F 1F
					39 00 00 00 00 00 05 03 01 01 01 01
					15 00 00 00 00 00 02 6F 24
					39 00 00 00 00 00 08 E1 01 03 15 1E 2E 3E 48
					15 00 00 00 00 00 02 6F 2B
					39 00 00 00 00 00 05 49 75 B1 DB FF
					// 3d lut inpro L240
					39 00 00 00 00 00 06 F0 55 AA 52 08 00
					39 00 00 00 00 00 02 6F 02
					39 00 00 00 00 00 07 E6 00 01 00 BC 01 5E
					39 00 00 00 00 00 02 6F 17
					39 00 00 00 00 00 02 E6 01
					39 00 00 00 00 00 06 F0 55 AA 52 08 00
					39 00 00 00 00 00 02 E6 80
					39 00 00 00 00 00 02 6F 00
					39 00 00 00 00 00 19 E7 00 00 00 00 00 00 00 00 00 00 00 00 00 00 00 00 00 00 00 00 00 00 00 00
					39 00 00 00 00 00 02 6F 18
					39 00 00 00 00 00 19 E7 00 40 40 40 40 40 40 40 40 40 40 40 40 40 40 40 40 40 40 40 40 40 40 40
					39 00 00 00 00 00 02 6F 30
					39 00 00 00 00 00 19 E7 40 40 80 80 80 80 80 80 80 80 80 80 80 80 80 80 80 80 80 80 80 80 80 80
					39 00 00 00 00 00 02 6F 48
					39 00 00 00 00 00 19 E7 80 80 80 C0 C0 C0 C0 C0 C0 C0 C0 C0 C0 C0 C0 C0 C0 C0 C0 C0 C0 C0 C0 C0
					39 00 00 00 00 00 02 6F 60
					39 00 00 00 00 00 19 E7 C0 C0 C0 C0 FF FF FF FF FF FF FF FF FF FF FF FF FF FF FF FF FF FF FF FF
					39 00 00 00 00 00 02 6F 78
					39 00 00 00 00 00 19 E7 FF FF FF FF FF 00 00 00 00 00 40 40 40 40 40 80 80 80 80 80 C0 C0 C0 C0
					39 00 00 00 00 00 02 6F 90
					39 00 00 00 00 00 19 E7 C0 FF FF FF FF FF 00 00 00 00 00 40 40 40 40 40 80 80 80 80 80 C0 C0 C0
					39 00 00 00 00 00 02 6F A8
					39 00 00 00 00 00 19 E7 C0 C0 FF FF FF FF FF 00 00 00 00 00 40 40 40 40 40 80 80 80 80 80 C0 C0
					39 00 00 00 00 00 02 6F C0
					39 00 00 00 00 00 19 E7 C0 C0 C0 FF FF FF FF FF 00 00 00 00 00 40 40 40 40 40 80 80 80 80 80 C0
					39 00 00 00 00 00 02 6F D8
					39 00 00 00 00 00 19 E7 C0 C0 C0 C0 FF FF FF FF FF 00 00 00 00 00 40 40 40 40 40 80 80 80 80 80
					39 00 00 00 00 00 02 6F 00
					39 00 00 00 00 00 19 E8 C0 C0 C0 C0 C0 FF FF FF FF FF 00 40 80 C0 FF 00 40 80 C0 FF 00 40 80 C0
					39 00 00 00 00 00 02 6F 18
					39 00 00 00 00 00 19 E8 FF 00 40 80 C0 FF 00 40 80 C0 FF 00 40 80 C0 FF 00 40 80 C0 FF 00 40 80
					39 00 00 00 00 00 02 6F 30
					39 00 00 00 00 00 19 E8 C0 FF 00 40 80 C0 FF 00 40 80 C0 FF 00 40 80 C0 FF 00 40 80 C0 FF 00 40
					39 00 00 00 00 00 02 6F 48
					39 00 00 00 00 00 19 E8 80 C0 FF 00 40 80 C0 FF 00 40 80 C0 FF 00 40 80 C0 FF 00 40 80 C0 FF 00
					39 00 00 00 00 00 02 6F 60
					39 00 00 00 00 00 19 E8 40 80 C0 FF 00 40 80 C0 FF 00 40 80 C0 FF 00 40 80 C0 FF 00 40 80 C0 FF
					39 00 00 00 00 00 02 6F 78
					39 00 00 00 00 00 19 E8 00 40 80 C0 FF 00 40 80 C0 FF 00 40 80 C0 FF 08 10 18 20 28 30 38 48 50
					39 00 00 00 00 00 02 6F 90
					39 00 00 00 00 00 19 E8 58 60 68 70 78 88 90 98 A0 A8 B0 B8 C8 D0 D8 E0 E8 F0 F8 08 10 18 20 28
					39 00 00 00 00 00 02 6F A8
					39 00 00 00 00 00 19 E8 30 38 48 50 58 60 68 70 78 88 90 98 A0 A8 B0 B8 C8 D0 D8 E0 E8 F0 F8 08
					39 00 00 00 00 00 02 6F C0
					39 00 00 00 00 00 19 E8 10 18 20 28 30 38 48 50 58 60 68 70 78 88 90 98 A0 A8 B0 B8 C8 D0 D8 E0
					39 00 00 00 00 00 02 6F D8
					39 00 00 00 00 00 19 E8 E8 F0 F8 10 10 00 20 10 10 10 00 10 10 20 10 00 10 10 10 10 20 00 00 00
					39 00 00 00 00 00 02 E6 00
					39 00 00 00 00 00 06 F0 55 AA 52 08 00
					39 00 00 00 00 00 02 E6 81
					39 00 00 00 00 00 02 6F 00
					39 00 00 00 00 00 19 E7 00 00 00 00 00 00 00 00 00 00 00 00 00 00 00 00 00 00 00 00 00 00 00 00
					39 00 00 00 00 00 02 6F 18
					39 00 00 00 00 00 19 E7 00 40 40 40 40 40 40 40 40 40 40 40 40 40 40 40 40 40 40 40 40 40 40 40
					39 00 00 00 00 00 02 6F 30
					39 00 00 00 00 00 19 E7 40 40 80 80 80 80 80 80 80 80 80 80 80 80 80 80 80 80 80 80 80 80 80 80
					39 00 00 00 00 00 02 6F 48
					39 00 00 00 00 00 19 E7 80 80 80 C0 C0 C0 C0 C0 C0 C0 C0 C0 C0 C0 C0 C0 C0 C0 C0 C0 C0 C0 C0 C0
					39 00 00 00 00 00 02 6F 60
					39 00 00 00 00 00 19 E7 C0 C0 C0 C0 FF FF FF FF FF FF FF FF FF FF FF FF FF FF FF FF FF FF FF FF
					39 00 00 00 00 00 02 6F 78
					39 00 00 00 00 00 19 E7 FF FF FF FF FF 00 00 00 00 00 40 40 40 40 40 80 80 80 80 80 C0 C0 C0 C0
					39 00 00 00 00 00 02 6F 90
					39 00 00 00 00 00 19 E7 C0 FF FF FF FF FF 00 00 00 00 00 40 40 40 40 40 80 80 80 80 80 C0 C0 C0
					39 00 00 00 00 00 02 6F A8
					39 00 00 00 00 00 19 E7 C0 C0 FF FF FF FF FF 00 00 00 00 00 40 40 40 40 40 80 80 80 80 80 C0 C0
					39 00 00 00 00 00 02 6F C0
					39 00 00 00 00 00 19 E7 C0 C0 C0 FF FF FF FF FF 00 00 00 00 00 40 40 40 40 40 80 80 80 80 80 C0
					39 00 00 00 00 00 02 6F D8
					39 00 00 00 00 00 19 E7 C0 C0 C0 C0 FF FF FF FF FF 00 00 00 00 00 40 40 40 40 40 80 80 80 80 80
					39 00 00 00 00 00 02 6F 00
					39 00 00 00 00 00 19 E8 C0 C0 C0 C0 C0 FF FF FF FF FF 00 40 80 C0 FF 00 40 80 C0 FF 00 40 80 C0
					39 00 00 00 00 00 02 6F 18
					39 00 00 00 00 00 19 E8 FF 00 40 80 C0 FF 00 40 80 C0 FF 00 40 80 C0 FF 00 40 80 C0 FF 00 40 80
					39 00 00 00 00 00 02 6F 30
					39 00 00 00 00 00 19 E8 C0 FF 00 40 80 C0 FF 00 40 80 C0 FF 00 40 80 C0 FF 00 40 80 C0 FF 00 40
					39 00 00 00 00 00 02 6F 48
					39 00 00 00 00 00 19 E8 80 C0 FF 00 40 80 C0 FF 00 40 80 C0 FF 00 40 80 C0 FF 00 40 80 C0 FF 00
					39 00 00 00 00 00 02 6F 60
					39 00 00 00 00 00 19 E8 40 80 C0 FF 00 40 80 C0 FF 00 40 80 C0 FF 00 40 80 C0 FF 00 40 80 C0 FF
					39 00 00 00 00 00 02 6F 78
					39 00 00 00 00 00 19 E8 00 40 80 C0 FF 00 40 80 C0 FF 00 40 80 C0 FF 08 10 18 20 28 30 38 48 50
					39 00 00 00 00 00 02 6F 90
					39 00 00 00 00 00 19 E8 58 60 68 70 78 86 8E 95 9D A5 AE B7 C8 D0 D8 E0 E8 F0 F8 08 10 18 20 28
					39 00 00 00 00 00 02 6F A8
					39 00 00 00 00 00 19 E8 30 38 48 50 58 60 68 70 78 88 90 98 A0 A8 B0 B8 C6 CD D4 DC E5 EE F8 08
					39 00 00 00 00 00 02 6F C0
					39 00 00 00 00 00 19 E8 10 18 20 28 30 38 48 50 58 60 68 70 78 88 90 98 A0 A8 B0 B8 C8 D0 D8 E0
					39 00 00 00 00 00 02 6F D8
					39 00 00 00 00 00 19 E8 E8 F0 F8 10 10 00 20 10 10 10 00 10 10 20 10 00 10 10 10 10 20 00 00 00
					39 00 00 00 00 00 02 E6 00
					39 00 00 00 00 00 06 F0 55 AA 52 08 00
					39 00 00 00 00 00 02 E6 82
					39 00 00 00 00 00 02 6F 00
					39 00 00 00 00 00 19 E7 00 00 00 00 00 00 00 00 00 00 00 00 00 00 00 00 00 00 00 00 00 00 00 00
					39 00 00 00 00 00 02 6F 18
					39 00 00 00 00 00 19 E7 00 40 40 40 40 40 40 40 40 40 40 40 40 40 40 40 40 40 40 40 40 40 40 40
					39 00 00 00 00 00 02 6F 30
					39 00 00 00 00 00 19 E7 40 40 80 80 80 80 80 80 80 80 80 80 80 80 80 80 80 80 80 80 80 80 80 80
					39 00 00 00 00 00 02 6F 48
					39 00 00 00 00 00 19 E7 80 80 80 C0 C0 C0 C0 C0 C0 C0 C0 C0 C0 C0 C0 C0 C0 C0 C0 C0 C0 C0 C0 C0
					39 00 00 00 00 00 02 6F 60
					39 00 00 00 00 00 19 E7 C0 C0 C0 C0 FF FF FF FF FF FF FF FF FF FF FF FF FF FF FF FF FF FF FF FF
					39 00 00 00 00 00 02 6F 78
					39 00 00 00 00 00 19 E7 FF FF FF FF FF 00 00 00 00 00 40 40 40 40 40 80 80 80 80 80 C0 C0 C0 C0
					39 00 00 00 00 00 02 6F 90
					39 00 00 00 00 00 19 E7 C0 FF FF FF FF FF 00 00 00 00 00 40 40 40 40 40 80 80 80 80 80 C0 C0 C0
					39 00 00 00 00 00 02 6F A8
					39 00 00 00 00 00 19 E7 C0 C0 FF FF FF FF FF 00 00 00 00 00 40 40 40 40 40 80 80 80 80 80 C0 C0
					39 00 00 00 00 00 02 6F C0
					39 00 00 00 00 00 19 E7 C0 C0 C0 FF FF FF FF FF 00 00 00 00 00 40 40 40 40 40 80 80 80 80 80 C0
					39 00 00 00 00 00 02 6F D8
					39 00 00 00 00 00 19 E7 C0 C0 C0 C0 FF FF FF FF FF 00 00 00 00 00 40 40 40 40 40 80 80 80 80 80
					39 00 00 00 00 00 02 6F 00
					39 00 00 00 00 00 19 E8 C0 C0 C0 C0 C0 FF FF FF FF FF 00 40 80 C0 FF 00 40 80 C0 FF 00 40 80 C0
					39 00 00 00 00 00 02 6F 18
					39 00 00 00 00 00 19 E8 FF 00 40 80 C0 FF 00 40 80 C0 FF 00 40 80 C0 FF 00 40 80 C0 FF 00 40 80
					39 00 00 00 00 00 02 6F 30
					39 00 00 00 00 00 19 E8 C0 FF 00 40 80 C0 FF 00 40 80 C0 FF 00 40 80 C0 FF 00 40 80 C0 FF 00 40
					39 00 00 00 00 00 02 6F 48
					39 00 00 00 00 00 19 E8 80 C0 FF 00 40 80 C0 FF 00 40 80 C0 FF 00 40 80 C0 FF 00 40 80 C0 FF 00
					39 00 00 00 00 00 02 6F 60
					39 00 00 00 00 00 19 E8 40 80 C0 FF 00 40 80 C0 FF 00 40 80 C0 FF 00 40 80 C0 FF 00 40 80 C0 FF
					39 00 00 00 00 00 02 6F 78
					39 00 00 00 00 00 19 E8 00 40 80 C0 FF 00 40 80 C0 FF 00 40 80 C0 FF 08 10 18 20 28 30 38 48 50
					39 00 00 00 00 00 02 6F 90
					39 00 00 00 00 00 19 E8 58 60 68 70 78 88 90 98 A0 A8 B0 B8 C8 D0 D8 E0 E8 F0 F8 08 10 18 20 28
					39 00 00 00 00 00 02 6F A8
					39 00 00 00 00 00 19 E8 30 38 48 50 58 60 68 70 78 88 90 98 A0 A8 B0 B8 C8 D0 D8 E0 E8 F0 F8 08
					39 00 00 00 00 00 02 6F C0
					39 00 00 00 00 00 19 E8 10 18 20 28 30 38 48 50 58 60 68 70 78 88 90 98 A0 A8 B0 B8 C8 D0 D8 E0
					39 00 00 00 00 00 02 6F D8
					39 00 00 00 00 00 19 E8 E8 F0 F8 10 10 00 20 10 10 10 00 10 10 20 10 00 10 10 10 10 20 00 00 00
					39 00 00 00 00 00 02 E6 00
					39 00 00 00 00 00 02 57 80
					//osc fixed
					39 00 00 00 00 00 06 F0 55 AA 52 08 01
					39 00 00 00 00 00 06 C3 DD 06 20 11 FF
					15 00 00 00 00 00 02 6F 05
					39 00 00 00 00 00 06 C3 00 06 20 11 FF
					15 00 00 00 00 00 02 6F 0A
					39 00 00 00 00 00 06 C3 00 07 0E 20 06
					15 00 00 00 00 00 02 6F 0F
					39 00 00 00 00 00 06 C3 44 19 07 11 18
					15 00 00 00 00 00 02 6F 14
					39 00 00 00 00 00 06 C3 06 5C 13 07 0E
					15 00 00 00 00 00 02 6F 19
					39 00 00 00 00 00 06 C3 20 06 44 19 07
					15 00 00 00 00 00 02 6F 1E
					39 00 00 00 00 00 06 C3 0E 20 06 44 19
					15 00 00 00 00 00 02 6F 23
					39 00 00 00 00 00 06 C3 07 0E 20 06 44
					15 00 00 00 00 00 02 6F 28
					15 00 00 00 00 00 02 C3 19
					//Modify power-off timing
					39 00 00 00 00 00 06 F0 55 AA 52 08 03
					15 00 00 00 00 00 02 6F 07
					15 00 00 00 00 00 02 C6 48
					//Light On
					39 00 00 00 78 00 01 11 // Sleep out
					39 00 00 00 00 00 01 29 // Display out
				];
				oplus,dsi-aod-off-command = [
					39 00 00 40 00 00 06 F0 55 AA 52 08 00
					39 00 00 40 00 00 02 38 00
					05 00 00 40 00 00 01 2C
					39 00 00 40 00 00 03 51 00 00
					39 00 00 40 00 00 06 F0 55 AA 52 08 08
					39 00 00 40 00 00 02 BE 03
					39 00 00 40 00 00 05 FF AA 55 A5 81
					39 00 00 40 00 00 02 6F 0B
					39 00 00 00 00 00 02 FD 04 //gmaconv on
				];
				oplus,dsi-panel-aod-off-insert-black-command = [
					39 00 00 40 00 00 06 F0 55 AA 52 08 00
					39 00 00 40 00 00 02 38 00
					39 00 00 40 00 00 03 51 00 00
					39 00 00 40 00 00 06 F0 55 AA 52 08 08
					39 00 00 40 00 00 02 BE 03
					39 00 00 40 00 00 05 FF AA 55 A5 81
					39 00 00 40 00 00 02 6F 0B
					39 00 00 00 00 00 02 FD 04 //gmaconv on
				];
				oplus,dsi-ultra-low-power-aod-on-command = [
					39 00 00 40 00 00 06 F0 55 AA 52 08 00
					39 00 00 40 00 00 02 6F 18
					39 00 00 00 00 00 06 BB 01 00 02 02 00
				];
				oplus,dsi-ultra-low-power-aod-off-command = [
					39 00 00 40 00 00 06 F0 55 AA 52 08 00
					39 00 00 40 00 00 02 6F 18
					39 00 00 00 00 00 06 BB 01 00 00 00 00
				];
				oplus,dsi-hbm-on-command = [
					39 00 00 00 00 00 03 51 0F FE
				];
				oplus,dsi-hbm-off-command = [
					39 00 00 00 00 00 03 51 0D BB
				];
				oplus,dsi-adfr-min-fps-120hz-command = [
					39 00 00 40 00 00 06 F0 55 AA 52 08 09
					15 00 00 40 00 00 02 6F 1C
					39 00 00 40 00 00 06 BD A0 89 84 02 15
					15 00 00 40 00 00 02 6F 21
					39 00 00 40 00 00 06 BD A0 89 84 02 15
					15 00 00 40 00 00 02 6F 26
					39 00 00 40 00 00 06 BD 14 09 04 86 97
					15 00 00 40 00 00 02 6F 2B
					39 00 00 40 00 00 06 BD 14 09 04 86 97
					15 00 00 40 00 00 02 6F 3A
					39 00 00 40 00 00 06 BD A0 89 84 02 15
					15 00 00 40 00 00 02 6F 3F
					39 00 00 40 00 00 06 BD A0 89 84 02 15
					15 00 00 40 00 00 02 6F 44
					39 00 00 40 00 00 06 BD 14 09 04 86 97
					15 00 00 40 00 00 02 6F 49
					39 00 00 40 00 00 06 BD 14 09 04 86 97
					15 00 00 40 00 00 02 6F 58
					39 00 00 40 00 00 06 BD A0 89 84 02 15
					15 00 00 40 00 00 02 6F 5D
					39 00 00 40 00 00 06 BD A0 89 84 02 15
					15 00 00 40 00 00 02 6F 62
					39 00 00 40 00 00 06 BD 14 09 04 86 97
					15 00 00 40 00 00 02 6F 67
					39 00 00 40 00 00 06 BD 14 09 04 86 97
					39 00 00 40 00 00 02 2F 30
					39 00 00 00 00 00 02 6D 00
				];
				oplus,dsi-adfr-min-fps-30hz-command = [
					39 00 00 40 00 00 06 F0 55 AA 52 08 09
					15 00 00 40 00 00 02 6F 1C
					39 00 00 40 00 00 06 BD 90 87 82 06 1C
					15 00 00 40 00 00 02 6F 21
					39 00 00 40 00 00 06 BD 90 87 82 06 1C
					15 00 00 40 00 00 02 6F 26
					39 00 00 40 00 00 06 BD 0A 07 02 86 97
					15 00 00 40 00 00 02 6F 2B
					39 00 00 40 00 00 06 BD 0A 07 02 86 97
					15 00 00 40 00 00 02 6F 3A
					39 00 00 40 00 00 06 BD 90 87 82 06 1C
					15 00 00 40 00 00 02 6F 3F
					39 00 00 40 00 00 06 BD 90 87 82 06 1C
					15 00 00 40 00 00 02 6F 44
					39 00 00 40 00 00 06 BD 0A 07 02 86 97
					15 00 00 40 00 00 02 6F 49
					39 00 00 40 00 00 06 BD 0A 07 02 86 97
					15 00 00 40 00 00 02 6F 58
					39 00 00 40 00 00 06 BD 90 87 82 06 1C
					15 00 00 40 00 00 02 6F 5D
					39 00 00 40 00 00 06 BD 90 87 82 06 1C
					15 00 00 40 00 00 02 6F 62
					39 00 00 40 00 00 06 BD 0A 07 02 86 97
					15 00 00 40 00 00 02 6F 67
					39 00 00 40 00 00 06 BD 0A 07 02 86 97
					39 00 00 40 00 00 02 2F 30
					39 00 00 00 00 00 02 6D 03
				];
				oplus,dsi-adfr-min-fps-10hz-command = [
					39 00 00 40 00 00 06 F0 55 AA 52 08 09
					15 00 00 40 00 00 02 6F 1C
					39 00 00 40 00 00 06 BD 90 87 82 06 1C
					15 00 00 40 00 00 02 6F 21
					39 00 00 40 00 00 06 BD 90 87 82 06 1C
					15 00 00 40 00 00 02 6F 26
					39 00 00 40 00 00 06 BD 0A 07 02 86 97
					15 00 00 40 00 00 02 6F 2B
					39 00 00 40 00 00 06 BD 0A 07 02 86 97
					15 00 00 40 00 00 02 6F 3A
					39 00 00 40 00 00 06 BD 90 87 82 06 1C
					15 00 00 40 00 00 02 6F 3F
					39 00 00 40 00 00 06 BD 90 87 82 06 1C
					15 00 00 40 00 00 02 6F 44
					39 00 00 40 00 00 06 BD 0A 07 02 86 97
					15 00 00 40 00 00 02 6F 49
					39 00 00 40 00 00 06 BD 0A 07 02 86 97
					15 00 00 40 00 00 02 6F 58
					39 00 00 40 00 00 06 BD 90 87 82 06 1C
					15 00 00 40 00 00 02 6F 5D
					39 00 00 40 00 00 06 BD 90 87 82 06 1C
					15 00 00 40 00 00 02 6F 62
					39 00 00 40 00 00 06 BD 0A 07 02 86 97
					15 00 00 40 00 00 02 6F 67
					39 00 00 40 00 00 06 BD 0A 07 02 86 97
					39 00 00 40 00 00 02 2F 30
					39 00 00 00 00 00 02 6D 05
				];
				oplus,dsi-adfr-min-fps-1hz-command = [
					39 00 00 40 00 00 06 F0 55 AA 52 08 09
					15 00 00 40 00 00 02 6F 1C
					39 00 00 40 00 00 06 BD 90 87 82 06 1C
					15 00 00 40 00 00 02 6F 21
					39 00 00 40 00 00 06 BD 90 87 82 06 1C
					15 00 00 40 00 00 02 6F 26
					39 00 00 40 00 00 06 BD 0A 07 02 86 97
					15 00 00 40 00 00 02 6F 2B
					39 00 00 40 00 00 06 BD 0A 07 02 86 97
					15 00 00 40 00 00 02 6F 3A
					39 00 00 40 00 00 06 BD 90 87 82 06 1C
					15 00 00 40 00 00 02 6F 3F
					39 00 00 40 00 00 06 BD 90 87 82 06 1C
					15 00 00 40 00 00 02 6F 44
					39 00 00 40 00 00 06 BD 0A 07 02 86 97
					15 00 00 40 00 00 02 6F 49
					39 00 00 40 00 00 06 BD 0A 07 02 86 97
					15 00 00 40 00 00 02 6F 58
					39 00 00 40 00 00 06 BD 90 87 82 06 1C
					15 00 00 40 00 00 02 6F 5D
					39 00 00 40 00 00 06 BD 90 87 82 06 1C
					15 00 00 40 00 00 02 6F 62
					39 00 00 40 00 00 06 BD 0A 07 02 86 97
					15 00 00 40 00 00 02 6F 67
					39 00 00 40 00 00 06 BD 0A 07 02 86 97
					39 00 00 40 00 00 02 2F 30
					39 00 00 00 00 00 02 6D 07
				];

				oplus,dsi-timing-switch-command-state = "dsi_hs_mode";
				oplus,dsi-on-command-state = "dsi_lp_mode";
				oplus,dsi-aod-off-command-state = "dsi_ls_mode";
				oplus,dsi-panel-aod-off-insert-black-command-state = "dsi_ls_mode";
				oplus,dsi-ultra-low-power-aod-on-command-state = "dsi_ls_mode";
				oplus,dsi-ultra-low-power-aod-off-command-state = "dsi_ls_mode";
				oplus,dsi-hbm-on-command-state = "dsi_hs_mode";
				oplus,dsi-hbm-off-command-state = "dsi_hs_mode";
				oplus,dsi-adfr-min-fps-120hz-command-state = "dsi_hs_mode";
				oplus,dsi-adfr-min-fps-30hz-command-state = "dsi_hs_mode";
				oplus,dsi-adfr-min-fps-10hz-command-state = "dsi_hs_mode";
				oplus,dsi-adfr-min-fps-1hz-command-state = "dsi_hs_mode";
				oplus,dsc-params-entries = <&dsc_params>;
				oplus,spr-params-entries = <&spr_params>;
				oplus,dyn-fps {
					switch_en = <1>;
					vact_timing_fps = <120>;
					apollo_limit_superior_us = <4900>;
					apollo_limit_inferior_us = <6750>;
					apollo_transfer_time_us = <6200>;
				};
				oplus,display-mode {
					display-mode@0 {
						hdisplay = <1216>;
						vdisplay = <2640>;
						fhd-hfp = <2>;
						fhd-hsa = <26>;
						fhd-hbp = <36>;
						fhd-vfp = <100>;
						fhd-vsa = <8>;
						fhd-vbp = <76>;
						hskew = <STANDARD_ADFR>;
					};
					display-mode@1 {
						hdisplay = <1080>;
						vdisplay = <2344>;
						fhd-hfp = <2>;
						fhd-hsa = <26>;
						fhd-hbp = <36>;
						fhd-vfp = <100>;
						fhd-vsa = <8>;
						fhd-vbp = <76>;
						hskew = <STANDARD_ADFR>;
					};
				};
			};
			timing@oa_fhd_120 {
				cell-index = <3>;
				oplus,dsi-panel-framerate = <120>;
				oplus,adfr-timing-type = <2>;
				oplus,dsi-panel-pllclk = <553>;
				oplus,cmd-null-pkt-en = <0>;
				oplus,cmd-null-pkt-len = <0>;
				oplus,merge-trig-offset = <333>;
				oplus,ofp-aod-off-setbacklight-delay = <4>;
				#include "panel-ac247-p-7-a0014-dsi-cmd-common.dtsi"
				oplus,dsi-timing-switch-command = [
					//120HZ
					39 00 00 40 00 00 06 F0 55 AA 52 08 00
					15 00 00 40 00 00 02 6F 03
					39 00 00 40 00 00 03 35 00 00
					15 00 00 40 00 00 02 6F 20
					39 00 00 40 00 00 09 BA 00 01 03 03 00 01 03 03
					15 00 00 40 00 00 02 6F 30
					39 00 00 40 00 00 09 BA 00 01 03 0B 00 01 03 0B
					15 00 00 40 00 00 02 6F 40
					39 00 00 40 00 00 09 BA 00 01 03 17 00 01 03 17
					15 00 00 40 00 00 02 6F 50
					39 00 00 40 00 00 09 BA 00 01 03 77 00 01 03 77
					15 00 00 40 00 00 02 2F 30
					15 00 00 40 00 00 02 6D 00 //120Hz
					// DC/PWM fix
					39 00 00 40 00 00 06 F0 55 AA 52 08 09
					15 00 00 40 00 00 02 6F 1C
					39 00 00 40 00 00 06 BD A0 89 84 02 15 //Comp0_R_Gray0~4_DBV1
					15 00 00 40 00 00 02 6F 21
					39 00 00 40 00 00 06 BD A0 89 84 02 15 //Comp0_R_Gray0~4_DBV2
					15 00 00 40 00 00 02 6F 26
					39 00 00 40 00 00 06 BD 14 09 04 86 97 //Comp0_R_Gray0~4_DBV3
					15 00 00 40 00 00 02 6F 2B
					39 00 00 40 00 00 06 BD 14 09 04 86 97 //Comp0_R_Gray0~4_DBV4
					15 00 00 40 00 00 02 6F 3A
					39 00 00 40 00 00 06 BD A0 89 84 02 15 //Comp0_G_Gray0~4_DBV1
					15 00 00 40 00 00 02 6F 3F
					39 00 00 40 00 00 06 BD A0 89 84 02 15 //Comp0_G_Gray0~4_DBV1
					15 00 00 40 00 00 02 6F 44
					39 00 00 40 00 00 06 BD 14 09 04 86 97 //Comp0_G_Gray0~4_DBV3
					15 00 00 40 00 00 02 6F 49
					39 00 00 40 00 00 06 BD 14 09 04 86 97 //Comp0_G_Gray0~4_DBV4
					15 00 00 40 00 00 02 6F 58
					39 00 00 40 00 00 06 BD A0 89 84 02 15 //Comp0_B_Gray0~4_DBV1
					15 00 00 40 00 00 02 6F 5D
					39 00 00 40 00 00 06 BD A0 89 84 02 15 //Comp0_B_Gray0~4_DBV1
					15 00 00 40 00 00 02 6F 62
					39 00 00 40 00 00 06 BD 14 09 04 86 97 //Comp0_B_Gray0~4_DBV3
					15 00 00 40 00 00 02 6F 67
					39 00 00 00 00 00 06 BD 14 09 04 86 97 //Comp0_B_Gray0~4_DBV4
				];
				oplus,dsi-on-command = [
					// init code
					39 00 00 00 00 00 05 FF AA 55 A5 81
					39 00 00 00 00 00 02 6F 0C
					39 00 00 00 00 00 02 FD 08
					39 00 00 00 00 00 02 6F 02
					39 00 00 00 00 00 02 F9 84
					39 00 00 00 00 00 02 6F 10
					39 00 00 00 00 00 02 FB 40
					39 00 00 00 00 00 05 FF AA 55 A5 80
					39 00 00 00 00 00 02 6F 48
					39 00 00 00 00 00 02 F2 00
					39 00 00 00 00 00 05 FF AA 55 A5 80
					39 00 00 00 00 00 02 6F 16
					39 00 00 00 00 00 03 F4 02 74
					39 00 00 00 00 00 05 FF AA 55 A5 80
					39 00 00 00 00 00 02 6F 42
					39 00 00 00 00 00 02 F4 00
					39 00 00 00 00 00 05 FF AA 55 A5 80
					39 00 00 00 00 00 02 6F 49
					39 00 00 00 00 00 02 F2 10
					39 00 00 00 00 00 05 FF AA 55 A5 81
					39 00 00 00 00 00 02 6F 05
					39 00 00 00 00 00 03 FE 3C 3C
					39 00 00 00 00 00 05 FF AA 55 A5 82
					39 00 00 00 00 00 02 6F 09
					39 00 00 00 00 00 02 F2 FF
					39 00 00 00 00 00 05 FF AA 55 A5 80
					39 00 00 00 00 00 02 6F 04
					39 00 00 00 00 00 02 F2 3C
					39 00 00 00 00 00 05 FF AA 55 A5 80
					39 00 00 00 00 00 02 6F 0A
					39 00 00 00 00 00 06 F6 70 70 70 70 70 //Power seq
					39 00 00 00 00 00 05 FF AA 55 A5 81
					39 00 00 00 00 00 02 6F 0D
					39 00 00 00 00 00 02 FB 80 // TE_opt
					39 00 00 00 00 00 06 F0 55 AA 52 08 01
					39 00 00 00 00 00 02 E5 00
					39 00 00 00 00 00 05 FF AA 55 A5 80
					39 00 00 00 00 00 02 6F 15
					39 00 00 00 00 00 03 F8 01 8C // DSPOSC=138.6MHz
					39 00 00 00 00 00 05 FF AA 55 A5 80
					39 00 00 00 00 00 02 6F 3E
					39 00 00 00 00 00 02 F8 00
					39 00 00 00 00 00 05 FF AA 55 A5 81
					39 00 00 00 00 00 02 6F 0B
					39 00 00 00 00 00 02 FD 04
					39 00 00 00 00 00 02 5A 01
					39 00 00 00 00 00 02 17 30
					39 00 00 00 00 00 03 5F 00 00
					39 00 00 00 00 00 02 35 00 // TE on
					39 00 00 00 00 00 0A 88 01 02 5F 09 4F 00 00 00 00
					39 00 00 00 00 00 02 53 20
					39 00 00 00 00 00 05 2A 00 00 04 BF
					39 00 00 00 00 00 05 2B 00 00 0A 4F
					39 00 00 00 00 00 02 90 03
					39 00 00 00 00 00 02 6F 01
					39 00 00 00 00 00 02 90 43
					39 00 00 00 00 00 13 91 AB A8 00 14 C2 00 02 31 02 05 00 08 05 0E 04 7B 10 E0 // VESA
					39 00 00 00 00 00 02 26 00
					39 00 00 00 00 00 02 6D 00
					39 00 00 00 00 00 02 6F 06
					39 00 00 00 00 00 02 6D 00
					// VFP/VBP SOP/GOP ON
					39 00 00 00 00 00 06 F0 55 AA 52 08 00
					15 00 00 00 00 00 02 6F 0D
					15 00 00 00 00 00 02 C2 0F
					//OSC：121.9-121.2 MHz
					39 00 00 00 00 00 05 FF AA 55 A5 80
					15 00 00 00 00 00 02 6F 31
					39 00 00 00 00 00 03 F8 01 B7
					// LFCC fix
					39 00 00 00 00 00 06 F0 55 AA 52 08 00
					15 00 00 00 00 00 02 6F 08
					15 00 00 00 00 00 02 B2 C0
					39 00 00 00 00 00 06 F0 55 AA 52 08 09
					//Comp_DBVPNTS0~5 = 423h,424h,48Ah,48Bh,4F0h,4F1h
					15 00 00 00 00 00 02 6F 01
					39 00 00 00 00 00 0A BD 44 23 24 44 8A 8B 44 F0 F1
					// Fixed TE
					15 00 00 00 00 00 02 5A 00
					15 00 00 00 00 00 02 6F 03
					15 00 00 00 00 00 02 5A 00
					39 00 00 00 00 00 03 44 00 00
					15 00 00 00 00 00 02 6F 04
					39 00 00 00 00 00 0D 44 00 00 00 00 00 00 00 00 00 00 00 00
					39 00 00 00 00 00 06 F0 55 AA 52 08 00
					15 00 00 00 00 00 02 BE 47
					// TEST TE
					39 00 00 00 00 00 06 F0 55 AA 52 08 00
					15 00 00 00 00 00 02 6F 01
					15 00 00 00 00 00 02 BE 54
					39 00 00 00 00 00 06 F0 55 AA 52 08 00
					15 00 00 00 00 00 02 6F 07
					39 00 00 00 00 00 06 B5 4E 2C 00 00 00 //Nor ELVSS 2.3V,ELVDD 4.8V
					15 00 00 00 00 00 02 6F 0C
					39 00 00 00 00 00 06 B5 4E 35 00 00 00 //AOD ELVSS 1.4V,ELVDD 4.8V
					//2F:30->6D:00 120Hz(Repeat 1 times) --> 120Hz
					39 00 00 00 00 00 06 F0 55 AA 52 08 00
					15 00 00 00 00 00 02 6F 03
					39 00 00 00 00 00 03 35 00 00
					15 00 00 00 00 00 02 6F 20
					39 00 00 00 00 00 09 BA 00 01 03 03 00 01 03 03
					15 00 00 00 00 00 02 6F 30
					39 00 00 00 00 00 09 BA 00 01 03 0B 00 01 03 0B
					15 00 00 00 00 00 02 6F 40
					39 00 00 00 00 00 09 BA 00 01 03 17 00 01 03 17
					15 00 00 00 00 00 02 6F 50
					39 00 00 00 00 00 09 BA 00 01 03 77 00 01 03 77
					15 00 00 00 00 00 02 2F 30
					15 00 00 00 00 00 02 6D 00 //120Hz
					// DC/PWM fix
					39 00 00 00 00 00 06 F0 55 AA 52 08 09
					15 00 00 00 00 00 02 6F 1C
					39 00 00 00 00 00 06 BD A0 89 84 02 15 //Comp0_R_Gray0~4_DBV1
					15 00 00 00 00 00 02 6F 21
					39 00 00 00 00 00 06 BD A0 89 84 02 15 //Comp0_R_Gray0~4_DBV2
					15 00 00 00 00 00 02 6F 26
					39 00 00 00 00 00 06 BD 14 09 04 86 97 //Comp0_R_Gray0~4_DBV3
					15 00 00 00 00 00 02 6F 2B
					39 00 00 00 00 00 06 BD 14 09 04 86 97 //Comp0_R_Gray0~4_DBV4
					15 00 00 00 00 00 02 6F 3A
					39 00 00 00 00 00 06 BD A0 89 84 02 15 //Comp0_G_Gray0~4_DBV1
					15 00 00 00 00 00 02 6F 3F
					39 00 00 00 00 00 06 BD A0 89 84 02 15 //Comp0_G_Gray0~4_DBV1
					15 00 00 00 00 00 02 6F 44
					39 00 00 00 00 00 06 BD 14 09 04 86 97 //Comp0_G_Gray0~4_DBV3
					15 00 00 00 00 00 02 6F 49
					39 00 00 00 00 00 06 BD 14 09 04 86 97 //Comp0_G_Gray0~4_DBV4
					15 00 00 00 00 00 02 6F 58
					39 00 00 00 00 00 06 BD A0 89 84 02 15 //Comp0_B_Gray0~4_DBV1
					15 00 00 00 00 00 02 6F 5D
					39 00 00 00 00 00 06 BD A0 89 84 02 15 //Comp0_B_Gray0~4_DBV1
					15 00 00 00 00 00 02 6F 62
					39 00 00 00 00 00 06 BD 14 09 04 86 97 //Comp0_B_Gray0~4_DBV3
					15 00 00 00 00 00 02 6F 67
					39 00 00 00 00 00 06 BD 14 09 04 86 97 //Comp0_B_Gray0~4_DBV4
					// fix odc green ghosting
					39 00 00 00 00 00 06 F0 55 AA 52 08 08
					39 00 00 00 00 00 05 E0 21 01 01 01
					39 00 00 00 00 00 02 6F 35
					39 00 00 00 00 00 02 E2 00
					39 00 00 00 00 00 02 6F 43
					39 00 00 00 00 00 02 E2 00
					39 00 00 00 00 00 02 6F 51
					39 00 00 00 00 00 02 E2 00
					39 00 00 00 00 00 02 6F 5F
					39 00 00 00 00 00 02 E2 00
					39 00 00 00 00 00 02 6F 6D
					39 00 00 00 00 00 02 E2 00
					39 00 00 00 00 00 02 6F 7B
					39 00 00 00 00 00 02 E2 00
					// Demura LLC impro
					39 00 00 00 00 00 06 F0 55 AA 52 08 04
					39 00 00 00 00 00 08 E1 87 07 07 03 03 03 03
					15 00 00 00 00 00 02 6F 07
					39 00 00 00 00 00 05 03 01 01 01 01
					15 00 00 00 00 00 02 6F 0C
					39 00 00 00 00 00 08 E1 00 00 00 00 00 00 00
					15 00 00 00 00 00 02 6F 13
					39 00 00 00 00 00 05 00 00 00 00 00
					15 00 00 00 00 00 02 6F 18
					39 00 00 00 00 00 08 E1 07 07 07 03 03 03 03
					15 00 00 00 00 00 02 6F 1F
					39 00 00 00 00 00 05 03 01 01 01 01
					15 00 00 00 00 00 02 6F 24
					39 00 00 00 00 00 08 E1 01 03 15 1E 2E 3E 48
					15 00 00 00 00 00 02 6F 2B
					39 00 00 00 00 00 05 49 75 B1 DB FF
					// 3d lut inpro L240
					39 00 00 00 00 00 06 F0 55 AA 52 08 00
					39 00 00 00 00 00 02 6F 02
					39 00 00 00 00 00 07 E6 00 01 00 BC 01 5E
					39 00 00 00 00 00 02 6F 17
					39 00 00 00 00 00 02 E6 01
					39 00 00 00 00 00 06 F0 55 AA 52 08 00
					39 00 00 00 00 00 02 E6 80
					39 00 00 00 00 00 02 6F 00
					39 00 00 00 00 00 19 E7 00 00 00 00 00 00 00 00 00 00 00 00 00 00 00 00 00 00 00 00 00 00 00 00
					39 00 00 00 00 00 02 6F 18
					39 00 00 00 00 00 19 E7 00 40 40 40 40 40 40 40 40 40 40 40 40 40 40 40 40 40 40 40 40 40 40 40
					39 00 00 00 00 00 02 6F 30
					39 00 00 00 00 00 19 E7 40 40 80 80 80 80 80 80 80 80 80 80 80 80 80 80 80 80 80 80 80 80 80 80
					39 00 00 00 00 00 02 6F 48
					39 00 00 00 00 00 19 E7 80 80 80 C0 C0 C0 C0 C0 C0 C0 C0 C0 C0 C0 C0 C0 C0 C0 C0 C0 C0 C0 C0 C0
					39 00 00 00 00 00 02 6F 60
					39 00 00 00 00 00 19 E7 C0 C0 C0 C0 FF FF FF FF FF FF FF FF FF FF FF FF FF FF FF FF FF FF FF FF
					39 00 00 00 00 00 02 6F 78
					39 00 00 00 00 00 19 E7 FF FF FF FF FF 00 00 00 00 00 40 40 40 40 40 80 80 80 80 80 C0 C0 C0 C0
					39 00 00 00 00 00 02 6F 90
					39 00 00 00 00 00 19 E7 C0 FF FF FF FF FF 00 00 00 00 00 40 40 40 40 40 80 80 80 80 80 C0 C0 C0
					39 00 00 00 00 00 02 6F A8
					39 00 00 00 00 00 19 E7 C0 C0 FF FF FF FF FF 00 00 00 00 00 40 40 40 40 40 80 80 80 80 80 C0 C0
					39 00 00 00 00 00 02 6F C0
					39 00 00 00 00 00 19 E7 C0 C0 C0 FF FF FF FF FF 00 00 00 00 00 40 40 40 40 40 80 80 80 80 80 C0
					39 00 00 00 00 00 02 6F D8
					39 00 00 00 00 00 19 E7 C0 C0 C0 C0 FF FF FF FF FF 00 00 00 00 00 40 40 40 40 40 80 80 80 80 80
					39 00 00 00 00 00 02 6F 00
					39 00 00 00 00 00 19 E8 C0 C0 C0 C0 C0 FF FF FF FF FF 00 40 80 C0 FF 00 40 80 C0 FF 00 40 80 C0
					39 00 00 00 00 00 02 6F 18
					39 00 00 00 00 00 19 E8 FF 00 40 80 C0 FF 00 40 80 C0 FF 00 40 80 C0 FF 00 40 80 C0 FF 00 40 80
					39 00 00 00 00 00 02 6F 30
					39 00 00 00 00 00 19 E8 C0 FF 00 40 80 C0 FF 00 40 80 C0 FF 00 40 80 C0 FF 00 40 80 C0 FF 00 40
					39 00 00 00 00 00 02 6F 48
					39 00 00 00 00 00 19 E8 80 C0 FF 00 40 80 C0 FF 00 40 80 C0 FF 00 40 80 C0 FF 00 40 80 C0 FF 00
					39 00 00 00 00 00 02 6F 60
					39 00 00 00 00 00 19 E8 40 80 C0 FF 00 40 80 C0 FF 00 40 80 C0 FF 00 40 80 C0 FF 00 40 80 C0 FF
					39 00 00 00 00 00 02 6F 78
					39 00 00 00 00 00 19 E8 00 40 80 C0 FF 00 40 80 C0 FF 00 40 80 C0 FF 08 10 18 20 28 30 38 48 50
					39 00 00 00 00 00 02 6F 90
					39 00 00 00 00 00 19 E8 58 60 68 70 78 88 90 98 A0 A8 B0 B8 C8 D0 D8 E0 E8 F0 F8 08 10 18 20 28
					39 00 00 00 00 00 02 6F A8
					39 00 00 00 00 00 19 E8 30 38 48 50 58 60 68 70 78 88 90 98 A0 A8 B0 B8 C8 D0 D8 E0 E8 F0 F8 08
					39 00 00 00 00 00 02 6F C0
					39 00 00 00 00 00 19 E8 10 18 20 28 30 38 48 50 58 60 68 70 78 88 90 98 A0 A8 B0 B8 C8 D0 D8 E0
					39 00 00 00 00 00 02 6F D8
					39 00 00 00 00 00 19 E8 E8 F0 F8 10 10 00 20 10 10 10 00 10 10 20 10 00 10 10 10 10 20 00 00 00
					39 00 00 00 00 00 02 E6 00
					39 00 00 00 00 00 06 F0 55 AA 52 08 00
					39 00 00 00 00 00 02 E6 81
					39 00 00 00 00 00 02 6F 00
					39 00 00 00 00 00 19 E7 00 00 00 00 00 00 00 00 00 00 00 00 00 00 00 00 00 00 00 00 00 00 00 00
					39 00 00 00 00 00 02 6F 18
					39 00 00 00 00 00 19 E7 00 40 40 40 40 40 40 40 40 40 40 40 40 40 40 40 40 40 40 40 40 40 40 40
					39 00 00 00 00 00 02 6F 30
					39 00 00 00 00 00 19 E7 40 40 80 80 80 80 80 80 80 80 80 80 80 80 80 80 80 80 80 80 80 80 80 80
					39 00 00 00 00 00 02 6F 48
					39 00 00 00 00 00 19 E7 80 80 80 C0 C0 C0 C0 C0 C0 C0 C0 C0 C0 C0 C0 C0 C0 C0 C0 C0 C0 C0 C0 C0
					39 00 00 00 00 00 02 6F 60
					39 00 00 00 00 00 19 E7 C0 C0 C0 C0 FF FF FF FF FF FF FF FF FF FF FF FF FF FF FF FF FF FF FF FF
					39 00 00 00 00 00 02 6F 78
					39 00 00 00 00 00 19 E7 FF FF FF FF FF 00 00 00 00 00 40 40 40 40 40 80 80 80 80 80 C0 C0 C0 C0
					39 00 00 00 00 00 02 6F 90
					39 00 00 00 00 00 19 E7 C0 FF FF FF FF FF 00 00 00 00 00 40 40 40 40 40 80 80 80 80 80 C0 C0 C0
					39 00 00 00 00 00 02 6F A8
					39 00 00 00 00 00 19 E7 C0 C0 FF FF FF FF FF 00 00 00 00 00 40 40 40 40 40 80 80 80 80 80 C0 C0
					39 00 00 00 00 00 02 6F C0
					39 00 00 00 00 00 19 E7 C0 C0 C0 FF FF FF FF FF 00 00 00 00 00 40 40 40 40 40 80 80 80 80 80 C0
					39 00 00 00 00 00 02 6F D8
					39 00 00 00 00 00 19 E7 C0 C0 C0 C0 FF FF FF FF FF 00 00 00 00 00 40 40 40 40 40 80 80 80 80 80
					39 00 00 00 00 00 02 6F 00
					39 00 00 00 00 00 19 E8 C0 C0 C0 C0 C0 FF FF FF FF FF 00 40 80 C0 FF 00 40 80 C0 FF 00 40 80 C0
					39 00 00 00 00 00 02 6F 18
					39 00 00 00 00 00 19 E8 FF 00 40 80 C0 FF 00 40 80 C0 FF 00 40 80 C0 FF 00 40 80 C0 FF 00 40 80
					39 00 00 00 00 00 02 6F 30
					39 00 00 00 00 00 19 E8 C0 FF 00 40 80 C0 FF 00 40 80 C0 FF 00 40 80 C0 FF 00 40 80 C0 FF 00 40
					39 00 00 00 00 00 02 6F 48
					39 00 00 00 00 00 19 E8 80 C0 FF 00 40 80 C0 FF 00 40 80 C0 FF 00 40 80 C0 FF 00 40 80 C0 FF 00
					39 00 00 00 00 00 02 6F 60
					39 00 00 00 00 00 19 E8 40 80 C0 FF 00 40 80 C0 FF 00 40 80 C0 FF 00 40 80 C0 FF 00 40 80 C0 FF
					39 00 00 00 00 00 02 6F 78
					39 00 00 00 00 00 19 E8 00 40 80 C0 FF 00 40 80 C0 FF 00 40 80 C0 FF 08 10 18 20 28 30 38 48 50
					39 00 00 00 00 00 02 6F 90
					39 00 00 00 00 00 19 E8 58 60 68 70 78 86 8E 95 9D A5 AE B7 C8 D0 D8 E0 E8 F0 F8 08 10 18 20 28
					39 00 00 00 00 00 02 6F A8
					39 00 00 00 00 00 19 E8 30 38 48 50 58 60 68 70 78 88 90 98 A0 A8 B0 B8 C6 CD D4 DC E5 EE F8 08
					39 00 00 00 00 00 02 6F C0
					39 00 00 00 00 00 19 E8 10 18 20 28 30 38 48 50 58 60 68 70 78 88 90 98 A0 A8 B0 B8 C8 D0 D8 E0
					39 00 00 00 00 00 02 6F D8
					39 00 00 00 00 00 19 E8 E8 F0 F8 10 10 00 20 10 10 10 00 10 10 20 10 00 10 10 10 10 20 00 00 00
					39 00 00 00 00 00 02 E6 00
					39 00 00 00 00 00 06 F0 55 AA 52 08 00
					39 00 00 00 00 00 02 E6 82
					39 00 00 00 00 00 02 6F 00
					39 00 00 00 00 00 19 E7 00 00 00 00 00 00 00 00 00 00 00 00 00 00 00 00 00 00 00 00 00 00 00 00
					39 00 00 00 00 00 02 6F 18
					39 00 00 00 00 00 19 E7 00 40 40 40 40 40 40 40 40 40 40 40 40 40 40 40 40 40 40 40 40 40 40 40
					39 00 00 00 00 00 02 6F 30
					39 00 00 00 00 00 19 E7 40 40 80 80 80 80 80 80 80 80 80 80 80 80 80 80 80 80 80 80 80 80 80 80
					39 00 00 00 00 00 02 6F 48
					39 00 00 00 00 00 19 E7 80 80 80 C0 C0 C0 C0 C0 C0 C0 C0 C0 C0 C0 C0 C0 C0 C0 C0 C0 C0 C0 C0 C0
					39 00 00 00 00 00 02 6F 60
					39 00 00 00 00 00 19 E7 C0 C0 C0 C0 FF FF FF FF FF FF FF FF FF FF FF FF FF FF FF FF FF FF FF FF
					39 00 00 00 00 00 02 6F 78
					39 00 00 00 00 00 19 E7 FF FF FF FF FF 00 00 00 00 00 40 40 40 40 40 80 80 80 80 80 C0 C0 C0 C0
					39 00 00 00 00 00 02 6F 90
					39 00 00 00 00 00 19 E7 C0 FF FF FF FF FF 00 00 00 00 00 40 40 40 40 40 80 80 80 80 80 C0 C0 C0
					39 00 00 00 00 00 02 6F A8
					39 00 00 00 00 00 19 E7 C0 C0 FF FF FF FF FF 00 00 00 00 00 40 40 40 40 40 80 80 80 80 80 C0 C0
					39 00 00 00 00 00 02 6F C0
					39 00 00 00 00 00 19 E7 C0 C0 C0 FF FF FF FF FF 00 00 00 00 00 40 40 40 40 40 80 80 80 80 80 C0
					39 00 00 00 00 00 02 6F D8
					39 00 00 00 00 00 19 E7 C0 C0 C0 C0 FF FF FF FF FF 00 00 00 00 00 40 40 40 40 40 80 80 80 80 80
					39 00 00 00 00 00 02 6F 00
					39 00 00 00 00 00 19 E8 C0 C0 C0 C0 C0 FF FF FF FF FF 00 40 80 C0 FF 00 40 80 C0 FF 00 40 80 C0
					39 00 00 00 00 00 02 6F 18
					39 00 00 00 00 00 19 E8 FF 00 40 80 C0 FF 00 40 80 C0 FF 00 40 80 C0 FF 00 40 80 C0 FF 00 40 80
					39 00 00 00 00 00 02 6F 30
					39 00 00 00 00 00 19 E8 C0 FF 00 40 80 C0 FF 00 40 80 C0 FF 00 40 80 C0 FF 00 40 80 C0 FF 00 40
					39 00 00 00 00 00 02 6F 48
					39 00 00 00 00 00 19 E8 80 C0 FF 00 40 80 C0 FF 00 40 80 C0 FF 00 40 80 C0 FF 00 40 80 C0 FF 00
					39 00 00 00 00 00 02 6F 60
					39 00 00 00 00 00 19 E8 40 80 C0 FF 00 40 80 C0 FF 00 40 80 C0 FF 00 40 80 C0 FF 00 40 80 C0 FF
					39 00 00 00 00 00 02 6F 78
					39 00 00 00 00 00 19 E8 00 40 80 C0 FF 00 40 80 C0 FF 00 40 80 C0 FF 08 10 18 20 28 30 38 48 50
					39 00 00 00 00 00 02 6F 90
					39 00 00 00 00 00 19 E8 58 60 68 70 78 88 90 98 A0 A8 B0 B8 C8 D0 D8 E0 E8 F0 F8 08 10 18 20 28
					39 00 00 00 00 00 02 6F A8
					39 00 00 00 00 00 19 E8 30 38 48 50 58 60 68 70 78 88 90 98 A0 A8 B0 B8 C8 D0 D8 E0 E8 F0 F8 08
					39 00 00 00 00 00 02 6F C0
					39 00 00 00 00 00 19 E8 10 18 20 28 30 38 48 50 58 60 68 70 78 88 90 98 A0 A8 B0 B8 C8 D0 D8 E0
					39 00 00 00 00 00 02 6F D8
					39 00 00 00 00 00 19 E8 E8 F0 F8 10 10 00 20 10 10 10 00 10 10 20 10 00 10 10 10 10 20 00 00 00
					39 00 00 00 00 00 02 E6 00
					39 00 00 00 00 00 02 57 80
					//osc fixed
					39 00 00 00 00 00 06 F0 55 AA 52 08 01
					39 00 00 00 00 00 06 C3 DD 06 20 11 FF
					15 00 00 00 00 00 02 6F 05
					39 00 00 00 00 00 06 C3 00 06 20 11 FF
					15 00 00 00 00 00 02 6F 0A
					39 00 00 00 00 00 06 C3 00 07 0E 20 06
					15 00 00 00 00 00 02 6F 0F
					39 00 00 00 00 00 06 C3 44 19 07 11 18
					15 00 00 00 00 00 02 6F 14
					39 00 00 00 00 00 06 C3 06 5C 13 07 0E
					15 00 00 00 00 00 02 6F 19
					39 00 00 00 00 00 06 C3 20 06 44 19 07
					15 00 00 00 00 00 02 6F 1E
					39 00 00 00 00 00 06 C3 0E 20 06 44 19
					15 00 00 00 00 00 02 6F 23
					39 00 00 00 00 00 06 C3 07 0E 20 06 44
					15 00 00 00 00 00 02 6F 28
					15 00 00 00 00 00 02 C3 19
					//Modify power-off timing
					39 00 00 00 00 00 06 F0 55 AA 52 08 03
					15 00 00 00 00 00 02 6F 07
					15 00 00 00 00 00 02 C6 48
					//Light On
					39 00 00 00 78 00 01 11 // Sleep out
					39 00 00 00 00 00 01 29 // Display out
				];
				oplus,dsi-aod-off-command = [
					39 00 00 40 00 00 06 F0 55 AA 52 08 00
					39 00 00 40 00 00 02 38 00
					05 00 00 40 00 00 01 2C
					39 00 00 40 00 00 03 51 00 00
					39 00 00 40 00 00 06 F0 55 AA 52 08 08
					39 00 00 40 00 00 02 BE 03
					39 00 00 40 00 00 05 FF AA 55 A5 81
					39 00 00 40 00 00 02 6F 0B
					39 00 00 00 00 00 02 FD 04 //gmaconv on
				];
				oplus,dsi-panel-aod-off-insert-black-command = [
					39 00 00 40 00 00 06 F0 55 AA 52 08 00
					39 00 00 40 00 00 02 38 00
					39 00 00 40 00 00 03 51 00 00
					39 00 00 40 00 00 06 F0 55 AA 52 08 08
					39 00 00 40 00 00 02 BE 03
					39 00 00 40 00 00 05 FF AA 55 A5 81
					39 00 00 40 00 00 02 6F 0B
					39 00 00 00 00 00 02 FD 04 //gmaconv on
				];
				oplus,dsi-hbm-on-command = [
					39 00 00 00 00 00 03 51 0F FE
				];
				oplus,dsi-hbm-off-command = [
					39 00 00 00 00 00 03 51 0D BB
				];
				oplus,dsi-adfr-min-fps-120hz-command = [
					39 00 00 40 00 00 06 F0 55 AA 52 08 09
					15 00 00 40 00 00 02 6F 1C
					39 00 00 40 00 00 06 BD A0 89 84 02 15
					15 00 00 40 00 00 02 6F 21
					39 00 00 40 00 00 06 BD A0 89 84 02 15
					15 00 00 40 00 00 02 6F 26
					39 00 00 40 00 00 06 BD 14 09 04 86 97
					15 00 00 40 00 00 02 6F 2B
					39 00 00 40 00 00 06 BD 14 09 04 86 97
					15 00 00 40 00 00 02 6F 3A
					39 00 00 40 00 00 06 BD A0 89 84 02 15
					15 00 00 40 00 00 02 6F 3F
					39 00 00 40 00 00 06 BD A0 89 84 02 15
					15 00 00 40 00 00 02 6F 44
					39 00 00 40 00 00 06 BD 14 09 04 86 97
					15 00 00 40 00 00 02 6F 49
					39 00 00 40 00 00 06 BD 14 09 04 86 97
					15 00 00 40 00 00 02 6F 58
					39 00 00 40 00 00 06 BD A0 89 84 02 15
					15 00 00 40 00 00 02 6F 5D
					39 00 00 40 00 00 06 BD A0 89 84 02 15
					15 00 00 40 00 00 02 6F 62
					39 00 00 40 00 00 06 BD 14 09 04 86 97
					15 00 00 40 00 00 02 6F 67
					39 00 00 40 00 00 06 BD 14 09 04 86 97
					39 00 00 40 00 00 02 2F 30
					39 00 00 00 00 00 02 6D 00
				];
				oplus,dsi-adfr-min-fps-30hz-command = [
					39 00 00 40 00 00 06 F0 55 AA 52 08 09
					15 00 00 40 00 00 02 6F 1C
					39 00 00 40 00 00 06 BD 90 87 82 06 1C
					15 00 00 40 00 00 02 6F 21
					39 00 00 40 00 00 06 BD 90 87 82 06 1C
					15 00 00 40 00 00 02 6F 26
					39 00 00 40 00 00 06 BD 0A 07 02 86 97
					15 00 00 40 00 00 02 6F 2B
					39 00 00 40 00 00 06 BD 0A 07 02 86 97
					15 00 00 40 00 00 02 6F 3A
					39 00 00 40 00 00 06 BD 90 87 82 06 1C
					15 00 00 40 00 00 02 6F 3F
					39 00 00 40 00 00 06 BD 90 87 82 06 1C
					15 00 00 40 00 00 02 6F 44
					39 00 00 40 00 00 06 BD 0A 07 02 86 97
					15 00 00 40 00 00 02 6F 49
					39 00 00 40 00 00 06 BD 0A 07 02 86 97
					15 00 00 40 00 00 02 6F 58
					39 00 00 40 00 00 06 BD 90 87 82 06 1C
					15 00 00 40 00 00 02 6F 5D
					39 00 00 40 00 00 06 BD 90 87 82 06 1C
					15 00 00 40 00 00 02 6F 62
					39 00 00 40 00 00 06 BD 0A 07 02 86 97
					15 00 00 40 00 00 02 6F 67
					39 00 00 40 00 00 06 BD 0A 07 02 86 97
					39 00 00 40 00 00 02 2F 30
					39 00 00 00 00 00 02 6D 03
				];
				oplus,dsi-multi-te-enable-command = [
					//Multi-te
					15 00 00 40 00 00 02 5A 00
					15 00 00 40 00 00 02 6F 03
					15 00 00 40 00 00 02 5A 33
					39 00 00 40 00 00 03 44 07 F3
					15 00 00 40 00 00 02 6F 04
					39 00 00 40 00 00 07 44 07 58 02 B0 03 AA
					15 00 00 40 00 00 02 6F 0A
					39 00 00 40 00 00 07 44 00 00 00 B0 03 AA
					39 00 00 40 00 00 06 F0 55 AA 52 08 00
					15 00 00 00 00 00 02 BE 47
				];
				oplus,dsi-multi-te-disable-command = [
					//Fixed-te
					39 00 00 40 00 00 02 5A 00
					39 00 00 40 00 00 02 6F 03
					39 00 00 40 00 00 02 5A 00
					39 00 00 40 00 00 03 40 00 00
					39 00 00 40 00 00 02 6F 04
					39 00 00 40 00 00 0D 44 00 00 00 00 00 00 00 00 00 00 00 00
					39 00 00 40 00 00 06 F0 55 AA 52 08 00
					39 00 00 00 00 00 02 BE 47
				];

				oplus,dsi-timing-switch-command-state = "dsi_hs_mode";
				oplus,dsi-on-command-state = "dsi_lp_mode";
				oplus,dsi-aod-off-command-state = "dsi_ls_mode";
				oplus,dsi-panel-aod-off-insert-black-command-state = "dsi_ls_mode";
				oplus,dsi-hbm-on-command-state = "dsi_hs_mode";
				oplus,dsi-hbm-off-command-state = "dsi_hs_mode";
				oplus,dsi-adfr-min-fps-120hz-command-state = "dsi_hs_mode";
				oplus,dsi-adfr-min-fps-30hz-command-state = "dsi_hs_mode";
				oplus,dsi-multi-te-disable-command-state = "dsi_hs_mode";
				oplus,dsi-multi-te-enable-command-state = "dsi_hs_mode";
				oplus,dsc-params-entries = <&dsc_params>;
				oplus,spr-params-entries = <&spr_params>;
				oplus,dyn-fps {
					switch_en = <1>;
					vact_timing_fps = <120>;
					apollo_limit_superior_us = <4900>;
					apollo_limit_inferior_us = <6750>;
					apollo_transfer_time_us = <6200>;
				};
				oplus,display-mode {
					oplus,display-mode@0 {
						hdisplay = <1216>;
						vdisplay = <2640>;
						fhd-hfp = <2>;
						fhd-hsa = <26>;
						fhd-hbp = <36>;
						fhd-vfp = <100>;
						fhd-vsa = <8>;
						fhd-vbp = <76>;
						hskew = <OPLUS_ADFR>;
					};
					oplus,display-mode@1 {
						hdisplay = <1080>;
						vdisplay = <2344>;
						fhd-hfp = <2>;
						fhd-hsa = <26>;
						fhd-hbp = <36>;
						fhd-vfp = <100>;
						fhd-vsa = <8>;
						fhd-vbp = <76>;
						hskew = <OPLUS_ADFR>;
					};
				};
			};
		};
	};
};

&panel_ac247_p_7_a0014_dsi_cmd {
	oplus,dsi-display-panel@0 {
		res-switch = <2>;
		/* Hardware config */
		oplus,panel-supply-entries = <&dsi_panel_pwr_supply>;
		oplus,panel-power-on-sequence = "1", "vddio", "5", "vddr", "5", "vci", "1";
		oplus,panel-power-off-sequence = "2", "vci", "5", "vddr", "5", "vddio", "1";
		reset-gpios = <&pio 90 0>;
		oplus,panel-reset-sequence = <2 10>, <1 1>, <0 1>, <1 20>;
		/* Panel config */
		oplus,dsi-serial-number-enabled = <1>;
		oplus,dsi-serial-number-index = <0>;
		oplus,dsi-serial-number-reg = <0xA3>;
		oplus,dsi-serial-number-read-count = <7>;
		oplus,dsi-serial-number-year-offset = <0>;
		oplus,partial-update-enable;
		oplus,mode-switch-h2l-delay;
		oplus,demura-dbv-enable;
		oplus,demura-dbv-cfg = <360>;
		oplus,lfcc-dbv-cfg = <1162>;
		/* PWM config */
		oplus,pwm-turbo-support = <1>; /* 0 not support, 1 with switch, 2 Global high frequency pwm without switch */
		oplus,pwm-switch-backlight-threshold = <0>;
		/* ADFR config */
		oplus-adfr-config = <0x201>;
		oplus-adfr-test-te-gpios = <&pio 103 0>;
		/* OFP config */
		oplus,ofp-fp-type = <0x410>;
		oplus,ofp-fp-local-hbm-calibration;
		oplus,ofp-longrui-aod-config = <0x0E>;
		/* ext_params */
		oplus,panel-type = <2>;
		oplus,keep_ulps = <1>;
		oplus,lane-swap-en = <0>;
		oplus,lane-swap = <
			MIPITX_PHY_LANE_0 MIPITX_PHY_LANE_1 MIPITX_PHY_LANE_3 MIPITX_PHY_LANE_2 MIPITX_PHY_LANE_CK MIPITX_PHY_LANE_0
			MIPITX_PHY_LANE_0 MIPITX_PHY_LANE_1 MIPITX_PHY_LANE_3 MIPITX_PHY_LANE_2 MIPITX_PHY_LANE_CK MIPITX_PHY_LANE_0
		>;
		oplus,lcm-color-mode = <MTK_DRM_COLOR_MODE_DISPLAY_P3>;
		oplus,output-mode = <MTK_PANEL_DSC_SINGLE_PORT>;
		oplus,panel-bpp = <10>;
		oplus,physical-width-um = <67123>;
		oplus,physical-height-um = <145728>;
		/* color */
		oplus,color-vivid-status;
		oplus,color-srgb-status;
		// oplus,color-softiris-status;
		// oplus,color-dual-panel-status;
		oplus,color-dual-brightness-status;
		oplus,color-oplus-calibrate-status;
		// oplus,color-samsung-status;
		oplus,color-loading-status;
		oplus,color-2nit-status;
		// oplus,color-nature-profession-status;
		/* ESD */
		oplus,cust-esd-check = <0>;
		oplus,esd-check-enable = <1>;
		oplus,esd_check_cmd = [
			0A
			0E
			AB
		];
		oplus,esd_check_count = [
			01
			01
			01
		];
		oplus,esd_check_value = [
			9C
			80
			00
		];
		oplus,esd_check_mask = [
			FF
			FF
			FF
		];
		/* MIPI error check config */
		/*
		 ** BIT(0): enable/disable check
		 ** BIT(1): enable/disable page switch
		 */
		oplus,mipi-err-check-config = <0x01>; // 0b0000'0111
		oplus,mipi-err-check-reg = [
			AB
		];
		oplus,mipi-err-check-value = [
			00 00
			00 40
		];
		oplus,mipi-err-check-count = [
			02
		];
		/*  32-bit binary flag
		 ** Bit value identified how to match the return value of each register.
		 ** The value 0(default) means equal, and the value 1 means not equal.
		 */
		oplus,mipi-err-check-match-modes = <0x00000000>;
	};
};
